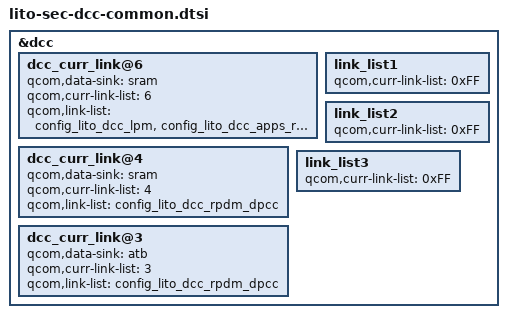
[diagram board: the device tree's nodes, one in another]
/* Copyright (c) 2019, The Linux Foundation. All rights reserved.
 *
 * This program is free software; you can redistribute it and/or modify
 * it under the terms of the GNU General Public License version 2 and
 * only version 2 as published by the Free Software Foundation.
 *
 * This program is distributed in the hope that it will be useful,
 * but WITHOUT ANY WARRANTY; without even the implied warranty of
 * MERCHANTABILITY or FITNESS FOR A PARTICULAR PURPOSE.  See the
 * GNU General Public License for more details.
 */

#include <dt-bindings/soc/qcom,dcc_v2.h>

#define config_lito_dcc_apps_rsc_pdc \
	/* APPS RSC */				\
	<DCC_READ 0x18200010 1 0>,	\
	<DCC_READ 0x18200030 1 0>,	\
	<DCC_READ 0x18200038 1 0>,	\
	<DCC_READ 0x18200040 1 0>,	\
	<DCC_READ 0x18200048 1 0>,	\
	<DCC_READ 0x18200400 1 0>,	\
	<DCC_READ 0x18200404 1 0>,	\
	<DCC_READ 0x18200408 1 0>,	\
	<DCC_READ 0x18220038 1 0>,	\
	<DCC_READ 0x18220040 1 0>,	\
	<DCC_READ 0x182200d0 1 0>,	\
	<DCC_READ 0x18230408 1 0>,	\
								\
	/* RPMH PDC */				\
	<DCC_READ 0xb201020 1 0>,	\
	<DCC_READ 0xb201024 1 0>,	\
	<DCC_READ 0xb20103c 1 0>,	\
	<DCC_READ 0xb204510 1 0>,	\
	<DCC_READ 0xb204514 1 0>,	\
	<DCC_READ 0xb204520 1 0>,	\
	<DCC_READ 0xb231020 1 0>,	\
	<DCC_READ 0xb231024 1 0>

#define config_lito_dcc_lpm		\
	 /* PCU Register */ 		\
	<DCC_READ 0x18000024 1 0>,	\
	<DCC_READ 0x18000040 1 0>,	\
	<DCC_READ 0x18010024 1 0>,	\
	<DCC_READ 0x18010040 1 0>,	\
	<DCC_READ 0x18020024 1 0>,	\
	<DCC_READ 0x18020040 1 0>,	\
	<DCC_READ 0x18030024 1 0>,	\
	<DCC_READ 0x18030040 1 0>,	\
	<DCC_READ 0x18040024 1 0>,	\
	<DCC_READ 0x18040040 1 0>,	\
	<DCC_READ 0x18050024 1 0>,	\
	<DCC_READ 0x18050040 1 0>,	\
	<DCC_READ 0x18060024 1 0>,	\
	<DCC_READ 0x18060040 1 0>,	\
	<DCC_READ 0x18070024 1 0>,	\
	<DCC_READ 0x18070040 1 0>,	\
	<DCC_READ 0x18080024 1 0>,	\
	<DCC_READ 0x18080040 1 0>,	\
	<DCC_READ 0x18080044 1 0>,	\
	<DCC_READ 0x18080048 1 0>,	\
	<DCC_READ 0x1808004c 1 0>,	\
	<DCC_READ 0x18080054 1 0>,	\
	<DCC_READ 0x1808006c 1 0>,	\
	<DCC_READ 0x18080070 1 0>,	\
	<DCC_READ 0x18080074 1 0>,	\
	<DCC_READ 0x18080078 1 0>,	\
	<DCC_READ 0x1808007c 1 0>,	\
	<DCC_READ 0x180800f4 1 0>,	\
	<DCC_READ 0x180800f8 1 0>,	\
	<DCC_READ 0x18080104 1 0>,	\
	<DCC_READ 0x18080118 1 0>,	\
	<DCC_READ 0x1808011c 1 0>,	\
	<DCC_READ 0x18080128 1 0>,	\
	<DCC_READ 0x1808012c 1 0>,	\
	<DCC_READ 0x18080130 1 0>,	\
	<DCC_READ 0x18080134 1 0>,	\
	<DCC_READ 0x18080138 1 0>,	\
	<DCC_READ 0x18080158 1 0>,	\
	<DCC_READ 0x1808015c 1 0>,	\
	<DCC_READ 0x18080168 1 0>,	\
	<DCC_READ 0x18080170 1 0>,	\
	<DCC_READ 0x18080174 1 0>,	\
	<DCC_READ 0x18080188 1 0>,	\
	<DCC_READ 0x1808018c 1 0>,	\
	<DCC_READ 0x18080198 1 0>,	\
	<DCC_READ 0x180801ac 1 0>,	\
	<DCC_READ 0x180801b0 1 0>,	\
	<DCC_READ 0x180801b4 1 0>,	\
	<DCC_READ 0x180801b8 1 0>,	\
	<DCC_READ 0x180801bc 1 0>,	\
	<DCC_READ 0x180801f0 1 0>,	\
	<DCC_READ 0x18280000 1 0>,	\
	<DCC_READ 0x18282000 1 0>,	\
	<DCC_READ 0x18284000 1 0>,	\
	<DCC_READ 0x18286000 1 0>

#define config_lito_dcc_core	\
	/* cpu_seq_sts3 */			\
	<DCC_READ 0x1800004C 1 0>,	\
	<DCC_READ 0x1801004C 1 0>,	\
	<DCC_READ 0x1802004C 1 0>,	\
	<DCC_READ 0x1803004C 1 0>,	\
	<DCC_READ 0x1804004C 1 0>,	\
	<DCC_READ 0x1805004C 1 0>,	\
	<DCC_READ 0x1806004C 1 0>,	\
	<DCC_READ 0x1807004C 1 0>,	\
								\
	/* core hang */				\
	<DCC_READ 0x1800005C 1 0>,	\
	<DCC_READ 0x1801005C 1 0>,	\
	<DCC_READ 0x1802005C 1 0>,	\
	<DCC_READ 0x1803005C 1 0>,	\
	<DCC_READ 0x1804005C 1 0>,	\
	<DCC_READ 0x1805005C 1 0>,	\
	<DCC_READ 0x1806005C 1 0>,	\
	<DCC_READ 0x1807005C 1 0>,	\
	<DCC_READ 0x17C0003C 1 0>,	\
								\
	/* CPRh */					\
	<DCC_READ 0x18101908 1 0>,	\
	<DCC_READ 0x18101C18 1 0>,	\
	<DCC_READ 0x18390810 1 0>,	\
	<DCC_READ 0x18390C50 1 0>,	\
	<DCC_READ 0x18390814 1 0>,	\
	<DCC_READ 0x18390C54 1 0>,	\
	<DCC_READ 0x18390818 1 0>,	\
	<DCC_READ 0x18390C58 1 0>,	\
	<DCC_READ 0x18393A84 2 0>,	\
	<DCC_READ 0x18100908 1 0>,	\
	<DCC_READ 0x18100C18 1 0>,	\
	<DCC_READ 0x183A0810 1 0>,	\
	<DCC_READ 0x183A0C50 1 0>,	\
	<DCC_READ 0x183A0814 1 0>,	\
	<DCC_READ 0x183A0C54 1 0>,	\
	<DCC_READ 0x183A0818 1 0>,	\
	<DCC_READ 0x183A0C58 1 0>,	\
	<DCC_READ 0x183A3A84 2 0>,	\
	<DCC_READ 0x18393500 1 0>,	\
	<DCC_READ 0x18393580 1 0>,	\
	<DCC_READ 0x183A3500 1 0>,	\
	<DCC_READ 0x183A3580 1 0>,	\
								\
	/* Silver / L3 / Gold+ PLL */	\
	<DCC_READ 0x18280000 4 0>,		\
	<DCC_READ 0x18284000 4 0>,		\
	<DCC_READ 0x18286000 4 0>,		\
									\
	/* Gold PLL */					\
	<DCC_READ 0x18282000 4 0>,		\
	<DCC_READ 0x18282028 1 0>,		\
	<DCC_READ 0x18282038 1 0>,		\
	<DCC_READ 0x18282080 5 0>,		\
	<DCC_READ 0x18286000 4 0>,		\
	<DCC_READ 0x18286028 1 0>,		\
	<DCC_READ 0x18286038 1 0>,		\
	<DCC_READ 0x18286080 5 0>,		\
									\
	/* rpmh */						\
	<DCC_READ 0x0C201244 1 0>,		\
	<DCC_READ 0x0C202244 1 0>,		\
	<DCC_READ 0x18300000 1 0>,		\
									\
	/* GOLD */						\
	<DCC_READ 	0x1829208C 1 	0>,	\
	<DCC_WRITE	0x1829209C 0x78 0>,	\
	<DCC_WRITE	0x1829209C 0x0  0>,	\
	<DCC_WRITE	0x18292048 0x1  0>,	\
	<DCC_WRITE	0x18292090 0x0  0>,	\
	<DCC_WRITE	0x18292090 0x25 0>,	\
	<DCC_READ	0x18292098 1 	0>,	\
	<DCC_WRITE	0x18292048 0x1D 0>,	\
	<DCC_WRITE	0x18292090 0x0  0>,	\
	<DCC_WRITE	0x18292090 0x25 0>,	\
	<DCC_READ	0x18292098 1	0>,	\
									\
	/* GOLD+ */						\
	<DCC_READ  0x1829608C 1    0>,	\
	<DCC_WRITE 0x1829609C 0x78 0>,	\
	<DCC_WRITE 0x1829609C 0x0  0>,	\
	<DCC_WRITE 0x18296048 0x1  0>,	\
	<DCC_WRITE 0x18296090 0x0  0>,	\
	<DCC_WRITE 0x18296090 0x25 0>,	\
	<DCC_READ  0x18296098 1	   0>,	\
	<DCC_WRITE 0x18296048 0x1D 0>,	\
	<DCC_WRITE 0x18296090 0x0  0>,	\
	<DCC_WRITE 0x18296090 0x25 0>

#define config_lito_dcc_osm			\
	/* APSS_OSM_RAIN0/RAIL1 */		\
	<DCC_READ 0x1832102c 1 0>,		\
	<DCC_READ 0x18321044 1 0>,		\
	<DCC_READ 0x18321700 1 0>,		\
	<DCC_READ 0x18321710 1 0>,		\
	<DCC_READ 0x1832176c 1 0>,		\
	<DCC_READ 0x18321818 1 0>,		\
	<DCC_READ 0x18321920 1 0>,		\
	<DCC_READ 0x18322c18 1 0>,		\
	<DCC_READ 0x1832302c 1 0>,		\
	<DCC_READ 0x18323044 1 0>,		\
	<DCC_READ 0x18323700 1 0>,		\
	<DCC_READ 0x18323710 1 0>,		\
	<DCC_READ 0x1832376c 1 0>,		\
	<DCC_READ 0x18323818 1 0>,		\
	<DCC_READ 0x18323920 1 0>,		\
	<DCC_READ 0x18324c18 1 0>,		\
	<DCC_READ 0x1832582c 1 0>,		\
	<DCC_READ 0x18325844 1 0>,		\
	<DCC_READ 0x18325f00 1 0>,		\
	<DCC_READ 0x18325f10 1 0>,		\
	<DCC_READ 0x18325f6c 1 0>,		\
	<DCC_READ 0x18326018 1 0>,		\
	<DCC_READ 0x18326120 1 0>,		\
	<DCC_READ 0x18327418 1 0>,		\
	<DCC_READ 0x1832782c 1 0>,		\
	<DCC_READ 0x18327844 1 0>,		\
	<DCC_READ 0x18327f00 1 0>,		\
	<DCC_READ 0x18327f10 1 0>,		\
	<DCC_READ 0x18327f6c 1 0>,		\
	<DCC_READ 0x18328018 1 0>,		\
	<DCC_READ 0x18328120 1 0>,		\
	<DCC_READ 0x18329418 1 0>

#define	config_lito_dcc_gemnoc		\
	/* GemNOC for lito start */		\
	<DCC_READ	0x9680000	3 0>,	\
	<DCC_LOOP	8 0 0>,				\
	<DCC_READ	0x9681000	1 0>,	\
	<DCC_LOOP	18 0 0>,			\
	<DCC_READ	0x09680078 	1 0>,	\
	<DCC_READ	0x9681008	12 0>,	\
	<DCC_LOOP	0xA6 0 0>,			\
	<DCC_READ	0x9681008 	1 0>,	\
	<DCC_READ	0x968100C 	1 0>,	\
	<DCC_LOOP	1 0 0>,				\
	<DCC_READ	0x968103C 	1 0>,	\
	<DCC_READ	0x9698100 	1 0>,	\
	<DCC_READ	0x9698104 	1 0>,	\
	<DCC_READ	0x9698108 	1 0>,	\
	<DCC_READ	0x9698110 	1 0>,	\
	<DCC_READ	0x9698120 	1 0>,	\
	<DCC_READ	0x9698124 	1 0>,	\
	<DCC_READ	0x9698128 	1 0>,	\
	<DCC_READ	0x969812c 	1 0>,	\
	<DCC_READ	0x9698130 	1 0>,	\
	<DCC_READ	0x9698134 	1 0>,	\
	<DCC_READ	0x9698138 	1 0>,	\
	<DCC_READ	0x969813c 	1 0>,	\
	<DCC_READ	0x968008C 	1 0>,	\
	<DCC_READ	0x9680088 	1 0>,	\
	<DCC_READ	0x96BA090 	1 0>

#define config_lito_dcc_noc			\
	<DCC_READ	0x0010500C	1 0>,	\
	<DCC_READ	0x00104144	1 0>,	\
	<DCC_READ	0x00105034	1 0>,	\
	/* Enable GCC_AGGRE_NOC_AHB_CBCR */	\
	<DCC_READ	0x00182008 	1 0>,	\
									\
	/* Enable clocks for SNOC sense registers */	\
	<DCC_WRITE	0x0010500C 0x1  0>,	\
	<DCC_WRITE	0x00104144 0x1  0>,	\
	<DCC_WRITE	0x00105034 0x1  0>,	\
	/* Enable GCC_AGGRE_NOC_AHB_CBCR */	\
	<DCC_WRITE	0x00182008 0x1  0>,	\
									\
	/* A1NOC */						\
	<DCC_READ	0x16e0000	1 0>,	\
	<DCC_READ	0x16e0004	1 0>,	\
	<DCC_READ	0x16e0288	1 0>,	\
	<DCC_READ	0x16e0290	1 0>,	\
	<DCC_READ	0x16e0300	1 0>,	\
	<DCC_READ	0x16e0408	1 0>,	\
	<DCC_READ	0x16e0410	1 0>,	\
	<DCC_READ	0x16e0420	1 0>,	\
	<DCC_READ	0x16e0424	1 0>,	\
	<DCC_READ	0x16e0428	1 0>,	\
	<DCC_READ	0x16e042c	1 0>,	\
	<DCC_READ	0x16e0430	1 0>,	\
	<DCC_READ	0x16e0434	1 0>,	\
	<DCC_READ	0x16e0438	1 0>,	\
	<DCC_READ	0x16e043c	1 0>,	\
	<DCC_READ	0x16e0688	1 0>,	\
	<DCC_READ	0x16e0690	1 0>,	\
	<DCC_READ	0x16e0700	1 0>,	\
	<DCC_READ	0x16e0888	1 0>,	\
	<DCC_READ	0x16e0890	1 0>,	\
	<DCC_READ	0x16e0900	1 0>,	\
	<DCC_READ	0x16e0904	1 0>,	\
	<DCC_READ	0x16e0a40	1 0>,	\
	<DCC_READ	0x16e0a48	1 0>,	\
	<DCC_READ	0x16e0a88	1 0>,	\
	<DCC_READ	0x16e0a90	1 0>,	\
	<DCC_READ	0x16e0b00	1 0>,	\
									\
	/* A2NOC */						\
	<DCC_READ 0x1700204	1 0>,		\
	<DCC_READ 0x1700240	1 0>,		\
	<DCC_READ 0x1700248	1 0>,		\
	<DCC_READ 0x1700288	1 0>,		\
	<DCC_READ 0x1700290	1 0>,		\
	<DCC_READ 0x1700300	1 0>,		\
	<DCC_READ 0x1700304	1 0>,		\
	<DCC_READ 0x1700308	1 0>,		\
	<DCC_READ 0x170030c	1 0>,		\
	<DCC_READ 0x1700310	1 0>,		\
	<DCC_READ 0x1700400	1 0>,		\
	<DCC_READ 0x1700404	1 0>,		\
	<DCC_READ 0x1700488	1 0>,		\
	<DCC_READ 0x1700490	1 0>,		\
	<DCC_READ 0x1700500	1 0>,		\
	<DCC_READ 0x1700504	1 0>,		\
	<DCC_READ 0x1700508	1 0>,		\
	<DCC_READ 0x170050c	1 0>,		\
	<DCC_READ 0x1700c00	1 0>,		\
	<DCC_READ 0x1700c04	1 0>,		\
	<DCC_READ 0x1700c08	1 0>,		\
	<DCC_READ 0x1700c10	1 0>,		\
	<DCC_READ 0x1700c20	1 0>,		\
	<DCC_READ 0x1700c24	1 0>,		\
	<DCC_READ 0x1700c28	1 0>,		\
	<DCC_READ 0x1700c2c	1 0>,		\
	<DCC_READ 0x1700c30	1 0>,		\
	<DCC_READ 0x1700c34	1 0>,		\
	<DCC_READ 0x1700c38	1 0>,		\
	<DCC_READ 0x1700c3c	1 0>,		\
									\
	/* SNOC */						\
	<DCC_READ	0x1620000	1 0>,	\
	<DCC_READ	0x1620004	1 0>,	\
	<DCC_READ	0x1620008	1 0>,	\
	<DCC_READ	0x1620010	1 0>,	\
	<DCC_READ	0x1620020	1 0>,	\
	<DCC_READ	0x1620024	1 0>,	\
	<DCC_READ	0x1620028	1 0>,	\
	<DCC_READ	0x162002c	1 0>,	\
	<DCC_READ	0x1620030	1 0>,	\
	<DCC_READ	0x1620034	1 0>,	\
	<DCC_READ	0x1620038	1 0>,	\
	<DCC_READ	0x162003c	1 0>,	\
	<DCC_READ	0x1620100	1 0>,	\
	<DCC_READ	0x1620104	1 0>,	\
	<DCC_READ	0x1620108	1 0>,	\
	<DCC_READ	0x1620110	1 0>,	\
	<DCC_READ	0x1620200	1 0>,	\
	<DCC_READ	0x1620204	1 0>,	\
	<DCC_READ	0x1620240	1 0>,	\
	<DCC_READ	0x1620248	1 0>,	\
	<DCC_READ	0x1620288	1 0>,	\
	<DCC_READ	0x162028c	1 0>,	\
	<DCC_READ	0x1620290	1 0>,	\
	<DCC_READ	0x1620294	1 0>,	\
	<DCC_READ	0x16202a8	1 0>,	\
	<DCC_READ	0x16202ac	1 0>,	\
	<DCC_READ	0x16202b0	1 0>,	\
	<DCC_READ	0x16202b4	1 0>,	\
	<DCC_READ	0x1620300	1 0>,	\
	<DCC_READ	0x1620400	1 0>,	\
	<DCC_READ	0x1620404	1 0>,	\
	<DCC_READ	0x1620488	1 0>,	\
	<DCC_READ	0x1620490	1 0>,	\
	<DCC_READ	0x1620500	1 0>,	\
	<DCC_READ	0x1620504	1 0>,	\
	<DCC_READ	0x1620508	1 0>,	\
	<DCC_READ	0x162050c	1 0>,	\
	<DCC_READ	0x1620510	1 0>,	\
	<DCC_READ	0x1620600	1 0>,	\
	<DCC_READ	0x1620604	1 0>,	\
	<DCC_READ	0x1620688	1 0>,	\
	<DCC_READ	0x1620690	1 0>,	\
	<DCC_READ	0x1620700	1 0>,	\
	<DCC_READ	0x1620704	1 0>,	\
	<DCC_READ	0x1620708	1 0>,	\
	<DCC_READ	0x162070c	1 0>,	\
	<DCC_READ	0x1620710	1 0>,	\
	<DCC_READ	0x1620800	1 0>,	\
	<DCC_READ	0x1620804	1 0>,	\
	<DCC_READ	0x1620900	1 0>,	\
	<DCC_READ	0x1620a00	1 0>,	\
	<DCC_READ	0x1620a04	1 0>,	\
	<DCC_READ	0x1620b00	1 0>,	\
	<DCC_READ	0x1620b04	1 0>,	\
	<DCC_READ	0x1620e00	1 0>,	\
	<DCC_READ	0x1620e04	1 0>,	\
	<DCC_READ	0x1620e88	1 0>,	\
	<DCC_READ	0x1620e90	1 0>,	\
	<DCC_READ	0x1620f00	1 0>,	\
	<DCC_READ	0x1639000	1 0>,	\
	<DCC_READ	0x1639004	1 0>,	\
	<DCC_READ	0x1639088	1 0>,	\
	<DCC_READ	0x1639090	1 0>,	\
	<DCC_READ	0x1639100	1 0>,	\
									\
	/* LPASS AGNOC */				\
	<DCC_READ	0x3c41800	1 0>,	\
	<DCC_READ	0x3c41804	1 0>,	\
	<DCC_READ	0x3c41880	1 0>,	\
	<DCC_READ	0x3c41888	1 0>,	\
	<DCC_READ	0x3c41890	1 0>,	\
	<DCC_READ	0x3c41900	1 0>,	\
	<DCC_READ	0x3c41a00	1 0>,	\
	<DCC_READ	0x3c41a04	1 0>,	\
	<DCC_READ	0x3c41a40	1 0>,	\
	<DCC_READ	0x3c41a48	1 0>,	\
	<DCC_READ	0x3c41c00	1 0>,	\
	<DCC_READ	0x3c41c04	1 0>,	\
	<DCC_READ	0x3c41d00	1 0>,	\
	<DCC_READ	0x3c42680	1 0>,	\
	<DCC_READ	0x3c42684	1 0>,	\
	<DCC_READ	0x3c42688	1 0>,	\
	<DCC_READ	0x3c42690	1 0>,	\
	<DCC_READ	0x3c42698	1 0>,	\
	<DCC_READ	0x3c426a0	1 0>,	\
	<DCC_READ	0x3c426a4	1 0>,	\
	<DCC_READ	0x3c426a8	1 0>,	\
	<DCC_READ	0x3c426ac	1 0>,	\
	<DCC_READ	0x3c426b0	1 0>,	\
	<DCC_READ	0x3c426b4	1 0>,	\
	<DCC_READ	0x3c426b8	1 0>,	\
	<DCC_READ	0x3c426bc	1 0>,	\
									\
	/* MMSS NOC */					\
	<DCC_READ 0x1740000 1 0>,  \
	<DCC_READ 0x1740004 1 0>,  \
	<DCC_READ 0x1740008 1 0>,  \
	<DCC_READ 0x1740010 1 0>,  \
	<DCC_READ 0x1740018 1 0>,  \
	<DCC_READ 0x1740020 1 0>,  \
	<DCC_READ 0x1740024 1 0>,  \
	<DCC_READ 0x1740028 1 0>,  \
	<DCC_READ 0x174002c 1 0>,  \
	<DCC_READ 0x1740030 1 0>,  \
	<DCC_READ 0x1740034 1 0>,  \
	<DCC_READ 0x1740038 1 0>,  \
	<DCC_READ 0x174003c 1 0>,  \
	<DCC_READ 0x1740240 1 0>,  \
	<DCC_READ 0x1740248 1 0>,  \
	<DCC_READ 0x1740280 1 0>,  \
	<DCC_READ 0x1740288 1 0>,  \
	<DCC_READ 0x1740290 1 0>,  \
	<DCC_READ 0x1740300 1 0>,  \
	<DCC_READ 0x1740304 1 0>,  \
	<DCC_READ 0x1740308 1 0>,  \
	<DCC_READ 0x174030c 1 0>,  \
	<DCC_READ 0x1740310 1 0>,  \
	<DCC_READ 0x1740314 1 0>,  \
	<DCC_READ 0x1740318 1 0>,  \
					\
	/* DDR NOC */								\
	<DCC_READ 0x010B8020 1 0>,  \
	<DCC_READ 0x010B8024 1 0>,  \
	<DCC_READ 0x010B8028 1 0>,  \
	<DCC_READ 0x010B802C 1 0>,  \
	<DCC_READ 0x010B8030 1 0>,  \
	<DCC_READ 0x010B8034 1 0>,  \
	<DCC_READ 0x010B8038 1 0>,  \
	<DCC_READ 0x010B803C 1 0>,  \
	<DCC_READ 0x010B8050 1 0>,  \
					\
	/* SMMU NOC */							\
	<DCC_READ 0x010B80A0 1 0>,  \
	<DCC_READ 0x010B80A4 1 0>,  \
	<DCC_READ 0x010B80A8 1 0>,  \
	<DCC_READ 0x010B80AC 1 0>,  \
	<DCC_READ 0x010B80B0 1 0>,  \
	<DCC_READ 0x010B80B4 1 0>,  \
	<DCC_READ 0x010B80B8 1 0>,  \
	<DCC_READ 0x010B80BC 1 0>,  \
	<DCC_READ 0x010B80E0 1 0>,  \
					\
	/* GEMNOC */					\
	<DCC_READ 0x9681010 1 0>,		\
	<DCC_READ 0x9681014 1 0>,		\
	<DCC_READ 0x9681018 1 0>,		\
	<DCC_READ 0x968101c 1 0>,		\
	<DCC_READ 0x9681020 1 0>,		\
	<DCC_READ 0x9681024 1 0>,		\
	<DCC_READ 0x9681028 1 0>,		\
	<DCC_READ 0x968102c 1 0>,		\
	<DCC_READ 0x9681030 1 0>,		\
	<DCC_READ 0x9681034 1 0>,		\
	<DCC_READ 0x968103c 1 0>,		\
	<DCC_READ 0x9692000 1 0>,		\
	<DCC_READ 0x9692004 1 0>,		\
	<DCC_READ 0x9692008 1 0>,		\
	<DCC_READ 0x9692040 1 0>,		\
	<DCC_READ 0x9692048 1 0>,		\
	<DCC_READ 0x9695000 1 0>,		\
	<DCC_READ 0x9695004 1 0>,		\
	<DCC_READ 0x9695080 1 0>,		\
	<DCC_READ 0x9695084 1 0>,		\
	<DCC_READ 0x9695088 1 0>,		\
	<DCC_READ 0x969508c 1 0>,		\
	<DCC_READ 0x9695090 1 0>,		\
	<DCC_READ 0x9695094 1 0>,		\
	<DCC_READ 0x96950a0 1 0>,		\
	<DCC_READ 0x96950a8 1 0>,		\
	<DCC_READ 0x96950b0 1 0>,		\
	<DCC_READ 0x9695100 1 0>,		\
	<DCC_READ 0x9695104 1 0>,		\
	<DCC_READ 0x9695108 1 0>,		\
	<DCC_READ 0x969510c 1 0>,		\
	<DCC_READ 0x9695110 1 0>,		\
	<DCC_READ 0x9695114 1 0>,		\
	<DCC_READ 0x9695118 1 0>,		\
	<DCC_READ 0x969511c 1 0>,		\
	<DCC_READ 0x9696000 1 0>,		\
	<DCC_READ 0x9696004 1 0>,		\
	<DCC_READ 0x9696080 1 0>,		\
	<DCC_READ 0x9696088 1 0>,		\
	<DCC_READ 0x9696090 1 0>,		\
	<DCC_READ 0x9696100 1 0>,		\
	<DCC_READ 0x9696104 1 0>,		\
	<DCC_READ 0x9696108 1 0>,		\
	<DCC_READ 0x969610c 1 0>,		\
	<DCC_READ 0x9696114 1 0>,		\
	<DCC_READ 0x9696118 1 0>,		\
	<DCC_READ 0x969611c 1 0>,		\
	<DCC_READ 0x9698000 1 0>,		\
	<DCC_READ 0x9698004 1 0>,		\
	<DCC_READ 0x9698008 1 0>,		\
	<DCC_READ 0x9698010 1 0>,		\
	<DCC_READ 0x9698100 1 0>,		\
	<DCC_READ 0x9698104 1 0>,		\
	<DCC_READ 0x9698108 1 0>,		\
	<DCC_READ 0x9698110 1 0>,		\
	<DCC_READ 0x9698118 1 0>,		\
	<DCC_READ 0x9698120 1 0>,		\
	<DCC_READ 0x9698124 1 0>,		\
	<DCC_READ 0x9698128 1 0>,		\
	<DCC_READ 0x969812c 1 0>,		\
	<DCC_READ 0x9698130 1 0>,		\
	<DCC_READ 0x9698134 1 0>,		\
	<DCC_READ 0x9698138 1 0>,		\
	<DCC_READ 0x969813c 1 0>,		\
	<DCC_READ 0x9698200 1 0>,		\
	<DCC_READ 0x9698204 1 0>,		\
	<DCC_READ 0x9698240 1 0>,		\
	<DCC_READ 0x9698244 1 0>,		\
	<DCC_READ 0x9698248 1 0>,		\
	<DCC_READ 0x969824c 1 0>,		\
	<DCC_READ 0x9232100 1 0>,		\
	<DCC_READ 0x9236044 1 0>,		\
	<DCC_READ 0x9236048 1 0>,		\
	<DCC_READ 0x923604C 1 0>,		\
	<DCC_READ 0x9236054 1 0>,		\
	<DCC_READ 0x9236040 1 0>,		\
	<DCC_READ 0x923A01C 1 0>,		\
	<DCC_READ 0x923A014 1 0>,		\
	<DCC_READ 0x923A004 1 0>,		\
	<DCC_READ 0x923A008 1 0>,		\
	<DCC_READ 0x923A00C 1 0>,		\
	<DCC_READ 0x923A010 1 0>,		\
	<DCC_READ 0x924202C 1 0>,		\
	<DCC_READ 0x922320C 1 0>,		\
	<DCC_READ 0x962320C 1 0>,		\
	<DCC_READ 0x9242014 1 0>,		\
	<DCC_READ 0x9242018 1 0>,		\
	<DCC_READ 0x924201C 1 0>,		\
	<DCC_READ 0x9242028 1 0>,		\
	<DCC_READ 0x924202C 1 0>,		\
	<DCC_READ 0x9242090 1 0>,		\
	<DCC_READ 0x9242094 1 0>,		\
	<DCC_READ 0x9242098 1 0>,		\
	<DCC_READ 0x92420A0 1 0>,		\
	<DCC_READ 0x92420B4 1 0>,		\
	<DCC_READ 0x92420C0 1 0>,		\
	<DCC_READ 0x92420D0 1 0>,		\
	<DCC_READ 0x92420D4 1 0>,		\
	<DCC_READ 0x92420D8 1 0>,		\
	<DCC_READ 0x9244054 1 0>,		\
	<DCC_READ 0x9236028 1 0>,		\
	<DCC_READ 0x923602C 1 0>,		\
	<DCC_READ 0x9236030 1 0>,		\
	<DCC_READ 0x9236034 1 0>,		\
	<DCC_READ 0x9236038 1 0>,		\
	<DCC_READ 0x923603C 1 0>,		\
	<DCC_READ 0x9236050 1 0>,		\
	<DCC_READ 0x9236058 1 0>,		\
	<DCC_READ 0x923605C 1 0>,		\
	<DCC_READ 0x9236060 1 0>,		\
	<DCC_READ 0x9236064 1 0>,		\
	<DCC_READ 0x9236068 1 0>,		\
	<DCC_READ 0x923606C 1 0>,		\
	<DCC_READ 0x9236070 1 0>,		\
	<DCC_READ 0x9236088 1 0>,		\
	<DCC_READ 0x92360A0 1 0>,		\
	<DCC_READ 0x92370A4 1 0>,		\
	<DCC_READ 0x923201C 1 0>,		\
	<DCC_READ 0x9232020 1 0>,		\
	<DCC_READ 0x9232024 1 0>,		\
	<DCC_READ 0x9232028 1 0>,		\
	<DCC_READ 0x923202C 1 0>,		\
	<DCC_READ 0x9232050 1 0>,		\
	<DCC_READ 0x9232104 1 0>,		\
	<DCC_READ 0x9232108 1 0>,		\
	<DCC_READ 0x923210C 1 0>,		\
	<DCC_READ 0x9232110 1 0>,		\
	<DCC_READ 0x9232114 1 0>,		\
	<DCC_READ 0x9200004 1 0>,		\
	<DCC_READ 0x9220338 1 0>,		\
	<DCC_READ 0x922033C 1 0>,		\
	<DCC_READ 0x9220344 1 0>,		\
	<DCC_READ 0x9220348 1 0>,		\
	<DCC_READ 0x9220480 1 0>,		\
	<DCC_READ 0x9222330 1 0>,		\
	<DCC_READ 0x9222334 1 0>,		\
	<DCC_READ 0x9222398 1 0>,		\
	<DCC_READ 0x92223A4 1 0>,		\
	<DCC_READ 0x9222400 1 0>,		\
	<DCC_READ 0x9222404 1 0>,		\
	<DCC_READ 0x9222408 1 0>,		\
	<DCC_READ 0x922240C 1 0>,		\
	<DCC_READ 0x9222410 1 0>,		\
	<DCC_READ 0x9222414 1 0>,		\
	<DCC_READ 0x9222600 1 0>,		\
	<DCC_READ 0x922320C 1 0>,		\
	<DCC_READ 0x9223214 1 0>,		\
	<DCC_READ 0x9223218 1 0>,		\
	<DCC_READ 0x9223220 1 0>,		\
	<DCC_READ 0x9223224 1 0>,		\
	<DCC_READ 0x9223228 1 0>,		\
	<DCC_READ 0x9223308 1 0>,		\
	<DCC_READ 0x9223318 1 0>,		\
	<DCC_READ 0x922358C 1 0>,		\
	<DCC_READ 0x92C2014 1 0>,		\
	<DCC_READ 0x92C2018 1 0>,		\
	<DCC_READ 0x92C201C 1 0>,		\
	<DCC_READ 0x92C2028 1 0>,		\
	<DCC_READ 0x92C202C 1 0>,		\
	<DCC_READ 0x92C2090 1 0>,		\
	<DCC_READ 0x92C2094 1 0>,		\
	<DCC_READ 0x92C2098 1 0>,		\
	<DCC_READ 0x92C20A0 1 0>,		\
	<DCC_READ 0x92C20B4 1 0>,		\
	<DCC_READ 0x92C20C0 1 0>,		\
	<DCC_READ 0x92C20D0 1 0>,		\
	<DCC_READ 0x92C20D4 1 0>,		\
	<DCC_READ 0x92C20D8 1 0>,		\
	<DCC_READ 0x92C4054 1 0>,		\
	<DCC_READ 0x92B6028 1 0>,		\
	<DCC_READ 0x92B602C 1 0>,		\
	<DCC_READ 0x92B6030 1 0>,		\
	<DCC_READ 0x92B6034 1 0>,		\
	<DCC_READ 0x92B6038 1 0>,		\
	<DCC_READ 0x92B603C 1 0>,		\
	<DCC_READ 0x92B6040 1 0>,		\
	<DCC_READ 0x92B6044 1 0>,		\
	<DCC_READ 0x92B6048 1 0>,		\
	<DCC_READ 0x92B604C 1 0>,		\
	<DCC_READ 0x92B6050 1 0>,		\
	<DCC_READ 0x92B6054 1 0>,		\
	<DCC_READ 0x92B6058 1 0>,		\
	<DCC_READ 0x92B605C 1 0>,		\
	<DCC_READ 0x92B6060 1 0>,		\
	<DCC_READ 0x92B6064 1 0>,		\
	<DCC_READ 0x92B6068 1 0>,		\
	<DCC_READ 0x92B606C 1 0>,		\
	<DCC_READ 0x92B6070 1 0>,		\
	<DCC_READ 0x92B6088 1 0>,		\
	<DCC_READ 0x92B60A0 1 0>,		\
	<DCC_READ 0x92B70A4 1 0>,		\
	<DCC_READ 0x92B201C 1 0>,		\
	<DCC_READ 0x92B2020 1 0>,		\
	<DCC_READ 0x92B2024 1 0>,		\
	<DCC_READ 0x92B2028 1 0>,		\
	<DCC_READ 0x92B202C 1 0>,		\
	<DCC_READ 0x92B2050 1 0>,		\
	<DCC_READ 0x92B2100 1 0>,		\
	<DCC_READ 0x92B2104 1 0>,		\
	<DCC_READ 0x92B2108 1 0>,		\
	<DCC_READ 0x92B210C 1 0>,		\
	<DCC_READ 0x92B2110 1 0>,		\
	<DCC_READ 0x92B2114 1 0>,		\
	<DCC_READ 0x9280004 1 0>,		\
	<DCC_READ 0x92A0338 1 0>,		\
	<DCC_READ 0x92A033C 1 0>,		\
	<DCC_READ 0x92A0344 1 0>,		\
	<DCC_READ 0x92A0348 1 0>,		\
	<DCC_READ 0x92A0480 1 0>,		\
	<DCC_READ 0x92A2330 1 0>,		\
	<DCC_READ 0x92A2334 1 0>,		\
	<DCC_READ 0x92A2398 1 0>,		\
	<DCC_READ 0x92A23A4 1 0>,		\
	<DCC_READ 0x92A2400 1 0>,		\
	<DCC_READ 0x92A2404 1 0>,		\
	<DCC_READ 0x92A2408 1 0>,		\
	<DCC_READ 0x92A240C 1 0>,		\
	<DCC_READ 0x92A2410 1 0>,		\
	<DCC_READ 0x92A2414 1 0>,		\
	<DCC_READ 0x92A2600 1 0>,		\
	<DCC_READ 0x92A320C 1 0>,		\
	<DCC_READ 0x92A3214 1 0>,		\
	<DCC_READ 0x92A3218 1 0>,		\
	<DCC_READ 0x92A3220 1 0>,		\
	<DCC_READ 0x92A3224 1 0>,		\
	<DCC_READ 0x92A3228 1 0>,		\
	<DCC_READ 0x92A3308 1 0>,		\
	<DCC_READ 0x92A3318 1 0>,		\
	<DCC_READ 0x92A358C 1 0>,		\
	<DCC_READ 0x92BA01C 1 0>,		\
	<DCC_READ 0x92BA014 1 0>,		\
	<DCC_READ 0x92BA004 1 0>,		\
	<DCC_READ 0x92BA008 1 0>,		\
	<DCC_READ 0x92BA00C 1 0>,		\
	<DCC_READ 0x92BA010 1 0>,		\
	<DCC_READ 0x963A01C 1 0>,		\
	<DCC_READ 0x964202C 1 0>,		\
	<DCC_READ 0x968008C 1 0>,		\
	<DCC_READ 0x9680088 1 0>,		\
	<DCC_READ 0x96950B0 1 0>,		\
	<DCC_READ 0x96AD010 1 0>,		\
	<DCC_READ 0x96AE010 1 0>,		\
	<DCC_READ 0x96AE090 1 0>,		\
	<DCC_READ 0x96AF010 1 0>,		\
	<DCC_READ 0x96B0010 1 0>,		\
	<DCC_READ 0x96B1010 1 0>,		\
	<DCC_READ 0x96B1090 1 0>,		\
	<DCC_READ 0x96B2010 1 0>,		\
	<DCC_READ 0x96B3010 1 0>,		\
	<DCC_READ 0x96B4010 1 0>,		\
	<DCC_READ 0x96B5010 1 0>,		\
	<DCC_READ 0x96B5090 1 0>,		\
	<DCC_READ 0x96B6010 1 0>,		\
	<DCC_READ 0x96B7010 1 0>,		\
	<DCC_READ 0x96B8010 1 0>,		\
	<DCC_READ 0x96AC008 1 0>,		\
	<DCC_READ 0x96AC040 1 0>,		\
	<DCC_READ 0x96AC044 1 0>,		\
	<DCC_READ 0x96AC048 1 0>,		\
	<DCC_READ 0x96AC04C 1 0>,		\
	<DCC_READ 0x96AC050 1 0>,		\
	<DCC_READ 0x96AC054 1 0>,		\
	<DCC_READ 0x96AC058 1 0>,		\
	<DCC_READ 0x96AC05C 1 0>,		\
	<DCC_READ 0x96AC060 1 0>,		\
	<DCC_READ 0x96AC064 1 0>,		\
	<DCC_READ 0x96AC068 1 0>,		\
	<DCC_READ 0x96AC06C 1 0>,		\
	<DCC_READ 0x96AC208 1 0>,		\
	<DCC_READ 0x96AC240 1 0>,		\
	<DCC_READ 0x96AC244 1 0>,		\
	<DCC_READ 0x96AC248 1 0>,		\
	<DCC_READ 0x96AC24C 1 0>,		\
	<DCC_READ 0x96AC250 1 0>,		\
	<DCC_READ 0x96AC254 1 0>,		\
	<DCC_READ 0x96AC258 1 0>,		\
	<DCC_READ 0x96AC25C 1 0>,		\
	<DCC_READ 0x96AC260 1 0>,		\
	<DCC_READ 0x96AC264 1 0>,		\
	<DCC_READ 0x96AC268 1 0>,		\
	<DCC_READ 0x96AC26C 1 0>,		\
	<DCC_READ 0x96950A8 1 0>,		\
	<DCC_READ 0x96950B0 1 0>,		\
	<DCC_READ 0x96950A0 1 0>,		\
	<DCC_READ 0x9180740 1 0>,		\
	<DCC_READ 0x9181740 1 0>,		\
	<DCC_READ 0x9182740 1 0>,		\
	<DCC_READ 0x9183740 1 0>,		\
	<DCC_READ 0x9184740 1 0>,		\
	<DCC_READ 0x9185740 1 0>,		\
	<DCC_READ 0x0148064 1 0>,		\
	<DCC_READ 0x014401C 1 0>,		\
	<DCC_READ 0x9681004 1 0>,		\
	<DCC_READ 0x9235030 1 0>,		\
	<DCC_READ 0x9235034 1 0>,		\
	<DCC_READ 0x92B5030 1 0>,		\
	<DCC_READ 0x92B5034 1 0>,		\
	<DCC_READ 0x9648074 1 0>,		\
	<DCC_READ 0x9248074 1 0>,		\
	<DCC_READ 0x92C8074 1 0>,		\
	<DCC_READ 0x9248068 1 0>,		\
	<DCC_READ 0x92C8068 1 0>,		\
	<DCC_READ 0x9648068 1 0>,		\
	<DCC_READ 0x92BA018 1 0>,		\
	<DCC_READ 0x963A018 1 0>,		\
	<DCC_READ 0x923A018 1 0>,		\
	<DCC_READ 0x9230010 1 0>,		\
	<DCC_READ 0x9230020 1 0>,		\
	<DCC_READ 0x9230030 1 0>,		\
	<DCC_READ 0x9230040 1 0>,		\
	<DCC_READ 0x923001C 1 0>,		\
	<DCC_READ 0x923002C 1 0>,		\
	<DCC_READ 0x923003C 1 0>,		\
	<DCC_READ 0x923004C 1 0>,		\
	<DCC_READ 0x17A70200 1 0>,		\
	<DCC_READ 0x17A90200 1 0>,		\
	<DCC_READ 0x17AB0200 1 0>,		\
	<DCC_READ 0x17AD0200 1 0>,		\
	<DCC_READ 0x17AF0200 1 0>,		\
	<DCC_READ 0x17B10200 1 0>,		\
	<DCC_READ 0x17B30200 1 0>,		\
	<DCC_READ 0x17B50200 1 0>

#define config_lito_dcc_gcc			\
	/* GCC */						\
	<DCC_READ 0x100000 13 0>,		\
	<DCC_READ 0x100040 	1	0>,		\
	<DCC_READ 0x100100  4 0>,		\
	<DCC_READ 0x101000 13 0>,		\
	<DCC_READ 0x10103c  1 0>,		\
	<DCC_READ 0x101040  1 0>,		\
	<DCC_READ 0x102000 13 0>,		\
	<DCC_READ 0x10203c  1 0>,		\
	<DCC_READ 0x102040  1 0>,		\
	<DCC_READ 0x103000 13 0>,		\
	<DCC_READ 0x10303c  1 0>,		\
	<DCC_READ 0x103040  1 0>,		\
	<DCC_READ 0x10401c  1 0>,		\
	<DCC_READ 0x105008  1 0>,		\
	<DCC_READ 0x10504c  1 0>,		\
	<DCC_READ 0x105064  1 0>,		\
	<DCC_READ 0x106100  1 0>,		\
	<DCC_READ 0x109004  1 0>,		\
	<DCC_READ 0x109008  1 0>,		\
	<DCC_READ 0x10900c  1 0>,		\
	<DCC_READ 0x109010  1 0>,		\
	<DCC_READ 0x109014  1 0>,		\
	<DCC_READ 0x109018  1 0>,		\
	<DCC_READ 0x10901c  1 0>,		\
	<DCC_READ 0x109020  1 0>,		\
	<DCC_READ 0x109024  1 0>,		\
	<DCC_READ 0x10904c  1 0>,		\
	<DCC_READ 0x10915c  1 0>,		\
	<DCC_READ 0x109160  1 0>,		\
	<DCC_READ 0x109464  1 0>,		\
	<DCC_READ 0x109468  1 0>,		\
	<DCC_READ 0x10946c  1 0>,		\
	<DCC_READ 0x109470  1 0>,		\
	<DCC_READ 0x109478  1 0>,		\
	<DCC_READ 0x113000  1 0>,		\
	<DCC_READ 0x113004  1 0>,		\
	<DCC_READ 0x113008  1 0>,		\
	<DCC_READ 0x11300c  1 0>,		\
	<DCC_READ 0x113010  1 0>,		\
	<DCC_READ 0x113014  1 0>,		\
	<DCC_READ 0x113018  1 0>,		\
	<DCC_READ 0x11301c  1 0>,		\
	<DCC_READ 0x113020  1 0>,		\
	<DCC_READ 0x113024  1 0>,		\
	<DCC_READ 0x113028  1 0>,		\
	<DCC_READ 0x11302c  1 0>,		\
	<DCC_READ 0x113030  1 0>,		\
	<DCC_READ 0x11303c  1 0>,		\
	<DCC_READ 0x113040  1 0>,		\
	<DCC_READ 0x117024  1 0>,		\
	<DCC_READ 0x117154  1 0>,		\
	<DCC_READ 0x117284  1 0>,		\
	<DCC_READ 0x1173b4  1 0>,		\
	<DCC_READ 0x1174e4  1 0>,		\
	<DCC_READ 0x117614  1 0>,		\
	<DCC_READ 0x118024  1 0>,		\
	<DCC_READ 0x118154  1 0>,		\
	<DCC_READ 0x118284  1 0>,		\
	<DCC_READ 0x1183b4  1 0>,		\
	<DCC_READ 0x1184e4  1 0>,		\
	<DCC_READ 0x118614  1 0>,		\
	<DCC_READ 0x11a000  1 0>,		\
	<DCC_READ 0x11a004  1 0>,		\
	<DCC_READ 0x11a008  1 0>,		\
	<DCC_READ 0x11a00c  1 0>,		\
	<DCC_READ 0x11a010  1 0>,		\
	<DCC_READ 0x11a014  1 0>,		\
	<DCC_READ 0x11a018  1 0>,		\
	<DCC_READ 0x11a01c  1 0>,		\
	<DCC_READ 0x11a020  1 0>,		\
	<DCC_READ 0x11a024  1 0>,		\
	<DCC_READ 0x11a028  1 0>,		\
	<DCC_READ 0x11a02c  1 0>,		\
	<DCC_READ 0x11a030  1 0>,		\
	<DCC_READ 0x11a03c  1 0>,		\
	<DCC_READ 0x11a040  1 0>,		\
	<DCC_READ 0x11b000  1 0>,		\
	<DCC_READ 0x11b004  1 0>,		\
	<DCC_READ 0x11b008  1 0>,		\
	<DCC_READ 0x11b00c  1 0>,		\
	<DCC_READ 0x11b010  1 0>,		\
	<DCC_READ 0x11b014  1 0>,		\
	<DCC_READ 0x11b018  1 0>,		\
	<DCC_READ 0x11b01c  1 0>,		\
	<DCC_READ 0x11b020  1 0>,		\
	<DCC_READ 0x11b024  1 0>,		\
	<DCC_READ 0x11b028  1 0>,		\
	<DCC_READ 0x11b02c  1 0>,		\
	<DCC_READ 0x11b030  1 0>,		\
	<DCC_READ 0x11b03c  1 0>,		\
	<DCC_READ 0x11b040  1 0>,		\
	<DCC_READ 0x11c000  1 0>,		\
	<DCC_READ 0x11c004  1 0>,		\
	<DCC_READ 0x11c008  1 0>,		\
	<DCC_READ 0x11c00c  1 0>,		\
	<DCC_READ 0x11c010  1 0>,		\
	<DCC_READ 0x11c014  1 0>,		\
	<DCC_READ 0x11c018  1 0>,		\
	<DCC_READ 0x11c01c  1 0>,		\
	<DCC_READ 0x11c020  1 0>,		\
	<DCC_READ 0x11c024  1 0>,		\
	<DCC_READ 0x11c028  1 0>,		\
	<DCC_READ 0x11c02c  1 0>,		\
	<DCC_READ 0x11c030  1 0>,		\
	<DCC_READ 0x11c03c  1 0>,		\
	<DCC_READ 0x11c040  1 0>,		\
	<DCC_READ 0x11d000  1 0>,		\
	<DCC_READ 0x11d004  1 0>,		\
	<DCC_READ 0x11d008  1 0>,		\
	<DCC_READ 0x11d00c  1 0>,		\
	<DCC_READ 0x11d010  1 0>,		\
	<DCC_READ 0x11d014  1 0>,		\
	<DCC_READ 0x11d018  1 0>,		\
	<DCC_READ 0x11d01c  1 0>,		\
	<DCC_READ 0x11d020  1 0>,		\
	<DCC_READ 0x11d024  1 0>,		\
	<DCC_READ 0x11d028  1 0>,		\
	<DCC_READ 0x11d02c  1 0>,		\
	<DCC_READ 0x11d030  1 0>,		\
	<DCC_READ 0x11d03c  1 0>,		\
	<DCC_READ 0x11d040  1 0>,		\
	<DCC_READ 0x120004  1 0>,		\
	<DCC_READ 0x123020  1 0>,		\
	<DCC_READ 0x127004  1 0>,		\
	<DCC_READ 0x135000  1 0>,		\
	<DCC_READ 0x13500c  1 0>,		\
	<DCC_READ 0x135010  1 0>,		\
	<DCC_READ 0x141024  1 0>,		\
	<DCC_READ 0x14401c  1 0>,		\
	<DCC_READ 0x144164  1 0>,		\
	<DCC_READ 0x144284  1 0>,		\
	<DCC_READ 0x1442a0  1 0>,		\
	<DCC_READ 0x1443d0  1 0>,		\
	<DCC_READ 0x145000  1 0>,		\
	<DCC_READ 0x145004  1 0>,		\
	<DCC_READ 0x145008  1 0>,		\
	<DCC_READ 0x145010  1 0>,		\
	<DCC_READ 0x145018  1 0>,		\
	<DCC_READ 0x145044  1 0>,		\
	<DCC_READ 0x145378  1 0>,		\
	<DCC_READ 0x14537c  1 0>,		\
	<DCC_READ 0x145380  1 0>,		\
	<DCC_READ 0x145384  1 0>,		\
	<DCC_READ 0x145398  1 0>,		\
	<DCC_READ 0x147000  1 0>,		\
	<DCC_READ 0x14700c  1 0>,		\
	<DCC_READ 0x147014  1 0>,		\
	<DCC_READ 0x148064  1 0>,		\
	<DCC_READ 0x17100c  1 0>,		\
	<DCC_READ 0x171010  1 0>,		\
	<DCC_READ 0x171018  1 0>,		\
	<DCC_READ 0x171250  1 0>,		\
	<DCC_READ 0x174000  1 0>,		\
	<DCC_READ 0x174004  1 0>,		\
	<DCC_READ 0x174008  1 0>,		\
	<DCC_READ 0x17400c  1 0>,		\
	<DCC_READ 0x174010  1 0>,		\
	<DCC_READ 0x174014  1 0>,		\
	<DCC_READ 0x174018  1 0>,		\
	<DCC_READ 0x17401c  1 0>,		\
	<DCC_READ 0x174020  1 0>,		\
	<DCC_READ 0x174024  1 0>,		\
	<DCC_READ 0x174028  1 0>,		\
	<DCC_READ 0x17402c  1 0>,		\
	<DCC_READ 0x174030  1 0>,		\
	<DCC_READ 0x17403c  1 0>,		\
	<DCC_READ 0x174040  1 0>,		\
	<DCC_READ 0x176000  1 0>,		\
	<DCC_READ 0x176004  1 0>,		\
	<DCC_READ 0x176008  1 0>,		\
	<DCC_READ 0x17600c  1 0>,		\
	<DCC_READ 0x176010  1 0>,		\
	<DCC_READ 0x176014  1 0>,		\
	<DCC_READ 0x176018  1 0>,		\
	<DCC_READ 0x17601c  1 0>,		\
	<DCC_READ 0x176020  1 0>,		\
	<DCC_READ 0x176024  1 0>,		\
	<DCC_READ 0x176028  1 0>,		\
	<DCC_READ 0x17602c  1 0>,		\
	<DCC_READ 0x176030  1 0>,		\
	<DCC_READ 0x17603c  1 0>,		\
	<DCC_READ 0x176040  1 0>,		\
	<DCC_READ 0x178040  1 0>,		\
	<DCC_READ 0x182010  1 0>,		\
	<DCC_READ 0x182884  1 0>,		\
	<DCC_READ 0x182888  1 0>,		\
	<DCC_READ 0x18288c  1 0>,		\
	<DCC_READ 0x182894  1 0>,		\
	<DCC_READ 0x182898  1 0>,		\
	<DCC_READ 0x18289c  1 0>,		\
	<DCC_READ 0x183004  1 0>,		\
	<DCC_READ 0x183008  1 0>,		\
	<DCC_READ 0x18300c  1 0>,		\
	<DCC_READ 0x183024  1 0>,		\
	<DCC_READ 0x183140  1 0>,		\
	<DCC_READ 0x18323c  1 0>,		\
	<DCC_READ 0x189004  1 0>,		\
	<DCC_READ 0x189008  1 0>,		\
	<DCC_READ 0x18900c  1 0>,		\
	<DCC_READ 0x189010  1 0>,		\
	<DCC_READ 0x189014  1 0>,		\
	<DCC_READ 0x189018  1 0>,		\
	<DCC_READ 0x18901c  1 0>,		\
	<DCC_READ 0x189024  1 0>,		\
	<DCC_READ 0x189044  1 0>,		\
	<DCC_READ 0x189164  1 0>,		\
	<DCC_READ 0x190004  1 0>,		\
	<DCC_READ 0x190008  1 0>,		\
	<DCC_READ 0x19000c  1 0>,		\
	<DCC_READ 0x190010  1 0>,		\
	<DCC_READ 0x190014  1 0>,		\
	<DCC_READ 0x190018  1 0>,		\
	<DCC_READ 0x191100  1 0>,		\
	<DCC_READ 0x192100  1 0>,		\
	<DCC_READ 0x193100  1 0>,		\
	<DCC_READ 0x194100  1 0>,		\
	<DCC_READ 0x195100  1 0>,		\
	<DCC_READ 0x196100  1 0>,		\
	<DCC_READ 0x197100  1 0>,		\
	<DCC_READ 0x19b100  1 0>,		\
	<DCC_READ 0x19c100  1 0>,		\
	<DCC_READ 0x3D91078 1 0>,		\
	<DCC_READ 0x3D95000 1 0>,		\
	<DCC_WRITE 0x10B008 0x1 0>

#define config_lito_dcc_pimem \
	<DCC_READ 0x610100 11 0>

#define config_lito_dcc_misc \
	<DCC_READ	0xC2A2040 1 0>

#define config_lito_dcc_ddr			\
	/* DDR -DCC starts here */		\
	/* Start Link list #6 */		\
	/* LLCC */						\
	<DCC_READ 0x9220480 1 0>,		\
	<DCC_READ 0x9232100 1 0>,		\
	<DCC_READ 0x92360b0 1 0>,		\
	<DCC_READ 0x9236044 4 0>,		\
	<DCC_READ 0x923e030 1 0>,		\
	<DCC_READ 0x9241000 1 0>,		\
	<DCC_READ 0x9248048 4 0>,		\
	<DCC_READ 0x9248058 4 0>,		\
	<DCC_READ 0x9236054 1 0>,		\
	<DCC_READ 0x9236040 1 0>,		\
	<DCC_READ 0x923A01C 1 0>,		\
	<DCC_READ 0x92B6054 1 0>,		\
	<DCC_READ 0x92B6040 1 0>,		\
	<DCC_READ 0x92BA01C 1 0>,		\
									\
	/* CABO */						\
	<DCC_READ 0x9260400	1 0>,		\
	<DCC_READ 0x9260410	1 0>,		\
	<DCC_READ 0x9260414	1 0>,		\
	<DCC_READ 0x9260418	1 0>,		\
	<DCC_READ 0x9260420	1 0>,		\
	<DCC_READ 0x9260424	1 0>,		\
	<DCC_READ 0x9260430	1 0>,		\
	<DCC_READ 0x9260440	1 0>,		\
	<DCC_READ 0x9260448	1 0>,		\
	<DCC_READ 0x92604a0	1 0>,		\
	<DCC_READ 0x92604B8	1 0>,		\
	<DCC_READ 0x9265804	1 0>,		\
	<DCC_READ 0x9266418	1 0>,		\
	<DCC_READ 0x92E0400	1 0>,		\
	<DCC_READ 0x92e0410	1 0>,		\
	<DCC_READ 0x92e0414	1 0>,		\
	<DCC_READ 0x92e0418	1 0>,		\
	<DCC_READ 0x92e0420	1 0>,		\
	<DCC_READ 0x92e0424	1 0>,		\
	<DCC_READ 0x92e0430	1 0>,		\
	<DCC_READ 0x92e0440	1 0>,		\
	<DCC_READ 0x92e0448	1 0>,		\
	<DCC_READ 0x92e04a0	1 0>,		\
	<DCC_READ 0x92E04B8	1 0>,		\
	<DCC_READ 0x92E5804	1 0>,		\
	<DCC_READ 0x92E6418	1 0>,		\
									\
	/* LLCC Broadcast */			\
	<DCC_READ	0x9600000	1 0>,	\
	<DCC_READ	0x9600004	1 0>,	\
	<DCC_READ	0x9601000	1 0>,	\
	<DCC_READ	0x9601004	1 0>,	\
	<DCC_READ	0x9602000	1 0>,	\
	<DCC_READ	0x9602004	1 0>,	\
	<DCC_READ	0x9603000	1 0>,	\
	<DCC_READ	0x9603004	1 0>,	\
	<DCC_READ	0x9604000	1 0>,	\
	<DCC_READ	0x9604004	1 0>,	\
	<DCC_READ	0x9605000	1 0>,	\
	<DCC_READ	0x9605004	1 0>,	\
	<DCC_READ	0x9606000	1 0>,	\
	<DCC_READ	0x9606004	1 0>,	\
	<DCC_READ	0x9607000	1 0>,	\
	<DCC_READ	0x9607004	1 0>,	\
	<DCC_READ	0x9608000	1 0>,	\
	<DCC_READ	0x9608004	1 0>,	\
	<DCC_READ	0x9609000	1 0>,	\
	<DCC_READ	0x9609004	1 0>,	\
	<DCC_READ	0x960a000	1 0>,	\
	<DCC_READ	0x960a004	1 0>,	\
	<DCC_READ	0x960b000	1 0>,	\
	<DCC_READ	0x960b004	1 0>,	\
	<DCC_READ	0x960c000	1 0>,	\
	<DCC_READ	0x960c004	1 0>,	\
	<DCC_READ	0x960d000	1 0>,	\
	<DCC_READ	0x960d004	1 0>,	\
	<DCC_READ	0x960e000	1 0>,	\
	<DCC_READ	0x960e004	1 0>,	\
	<DCC_READ	0x960f000	1 0>,	\
	<DCC_READ	0x960f004	1 0>,	\
	<DCC_READ	0x9610000	1 0>,	\
	<DCC_READ	0x9610004	1 0>,	\
	<DCC_READ	0x9611000	1 0>,	\
	<DCC_READ	0x9611004	1 0>,	\
	<DCC_READ	0x9612000	1 0>,	\
	<DCC_READ	0x9612004	1 0>,	\
	<DCC_READ	0x9613000	1 0>,	\
	<DCC_READ	0x9613004	1 0>,	\
	<DCC_READ	0x9614000	1 0>,	\
	<DCC_READ	0x9614004	1 0>,	\
	<DCC_READ	0x9615000	1 0>,	\
	<DCC_READ	0x9615004	1 0>,	\
	<DCC_READ	0x9616000	1 0>,	\
	<DCC_READ	0x9616004	1 0>,	\
	<DCC_READ	0x9617000	1 0>,	\
	<DCC_READ	0x9617004	1 0>,	\
	<DCC_READ	0x9618000	1 0>,	\
	<DCC_READ	0x9618004	1 0>,	\
	<DCC_READ	0x9619000	1 0>,	\
	<DCC_READ	0x9619004	1 0>,	\
	<DCC_READ	0x961a000	1 0>,	\
	<DCC_READ	0x961a004	1 0>,	\
	<DCC_READ	0x961b000	1 0>,	\
	<DCC_READ	0x961b004	1 0>,	\
	<DCC_READ	0x961c000	1 0>,	\
	<DCC_READ	0x961c004	1 0>,	\
	<DCC_READ	0x961d000	1 0>,	\
	<DCC_READ	0x961d004	1 0>,	\
	<DCC_READ	0x961e000	1 0>,	\
	<DCC_READ	0x961e004	1 0>,	\
	<DCC_READ	0x961f000	1 0>,	\
	<DCC_READ	0x961f004	1 0>,	\
									\
	/* SHRM / MCCC */				\
	<DCC_READ	0x9050008	1 0>,	\
	<DCC_READ	0x9050068	1 0>,	\
	<DCC_READ	0x9050078	1 0>,	\
	<DCC_READ	0x90b0280	1 0>,	\
	<DCC_READ	0x90b0288	1 0>,	\
	<DCC_READ	0x90b028c	1 0>,	\
	<DCC_READ	0x90b0290	1 0>,	\
	<DCC_READ	0x90b0294	1 0>,	\
	<DCC_READ	0x90b0298	1 0>,	\
	<DCC_READ	0x90b029c	1 0>,	\
	<DCC_READ	0x90b02a0	1 0>,	\
									\
	<DCC_READ	0x90C012C	1 0>,	\
	<DCC_READ	0x90C8040	1 0>,	\
									\
	/* LLCC1 */						\
	<DCC_READ	0x92a0480	1 0>,	\
	<DCC_READ	0x92b2100	1 0>,	\
	<DCC_READ	0x92b6044	1 0>,	\
	<DCC_READ	0x92b6048	1 0>,	\
	<DCC_READ	0x92b604c	1 0>,	\
	<DCC_READ	0x92b6050	1 0>,	\
	<DCC_READ	0x92b60b0	1 0>,	\
	<DCC_READ	0x92be030	1 0>,	\
	<DCC_READ	0x92c1000	1 0>,	\
	<DCC_READ	0x92C8048 4 0>,		\
	<DCC_READ	0x92c8058	1 0>,	\
	<DCC_READ	0x92c805c	1 0>,	\
	<DCC_READ	0x92c8060	1 0>,	\
	<DCC_READ	0x92c8064	1 0>
	
#define	config_lito_dcc_cam			\
	/* Cam CC */					\
	<DCC_READ 0x10B008  1 0>,		\
	<DCC_READ 0xAD0C1C4 1 0>,		\
	<DCC_READ 0xAD0C12C 1 0>,		\
	<DCC_READ 0xAD0C130 1 0>,		\
	<DCC_READ 0xAD0C144 1 0>,		\
	<DCC_READ 0xAD0C148 1 0>

#define config_lito_dcc_rsc_tcs		\
	/* APPS RSC TCS */				\
	<DCC_READ	0x18200d1c 1 0>,	\
	<DCC_READ	0x18200d34 1 0>,	\
	<DCC_READ	0x18200d38 1 0>,	\
	<DCC_READ	0x18200d3c 1 0>,	\
	<DCC_READ	0x18200d48 1 0>,	\
	<DCC_READ	0x18200d4c 1 0>,	\
	<DCC_READ	0x18200d50 1 0>,	\
	<DCC_READ	0x18200d5c 1 0>,	\
	<DCC_READ	0x18200d60 1 0>,	\
	<DCC_READ	0x18200d64 1 0>,	\
	<DCC_READ	0x18200d70 1 0>,	\
	<DCC_READ	0x18200d74 1 0>,	\
	<DCC_READ	0x18200d78 1 0>,	\
	<DCC_READ	0x18200fbc 1 0>,	\
	<DCC_READ	0x1820125c 1 0>,	\
	<DCC_READ	0x182014fc 1 0>,	\
	<DCC_READ	0x1822000c 1 0>,	\
	<DCC_READ	0x18220d00 1 0>,	\
	<DCC_READ	0x18220d04 1 0>,	\
	<DCC_READ	0x18220d14 1 0>,	\
	<DCC_READ	0x18220d18 1 0>,	\
	<DCC_READ	0x18220d1c 1 0>,	\
	<DCC_READ	0x18220fb4 1 0>,	\
	<DCC_READ	0x18220fb8 1 0>,	\
	<DCC_READ	0x18220fbc 1 0>,	\
	<DCC_READ	0x18221254 1 0>,	\
	<DCC_READ	0x18221258 1 0>,	\
	<DCC_READ	0x1822125c 1 0>,	\
	<DCC_READ	0x18221274 1 0>,	\
	<DCC_READ	0x18221278 1 0>,	\
	<DCC_READ	0x18221288 1 0>,	\
	<DCC_READ	0x1822128c 1 0>,	\
	<DCC_READ	0x1822129c 1 0>,	\
	<DCC_READ	0x182212a0 1 0>,	\
	<DCC_READ	0x182212b0 1 0>,	\
	<DCC_READ	0x182212b4 1 0>,	\
	<DCC_READ	0x182212c4 1 0>,	\
	<DCC_READ	0x182212c8 1 0>,	\
	<DCC_READ	0x182212d8 1 0>,	\
	<DCC_READ	0x182212dc 1 0>,	\
	<DCC_READ	0x182212ec 1 0>,	\
	<DCC_READ	0x182212f0 1 0>,	\
	<DCC_READ	0x18221300 1 0>,	\
	<DCC_READ	0x18221304 1 0>,	\
	<DCC_READ	0x18221314 1 0>,	\
	<DCC_READ	0x18221318 1 0>,	\
	<DCC_READ	0x18221328 1 0>,	\
	<DCC_READ	0x1822132c 1 0>,	\
	<DCC_READ	0x1822133c 1 0>,	\
	<DCC_READ	0x18221340 1 0>,	\
	<DCC_READ	0x18221350 1 0>,	\
	<DCC_READ	0x18221354 1 0>,	\
	<DCC_READ	0x18221364 1 0>,	\
	<DCC_READ	0x18221368 1 0>,	\
	<DCC_READ	0x18221378 1 0>,	\
	<DCC_READ	0x1822137c 1 0>,	\
	<DCC_READ	0x1822138c 1 0>,	\
	<DCC_READ	0x18221390 1 0>,	\
	<DCC_READ	0x182213a0 1 0>,	\
	<DCC_READ	0x182213a4 1 0>,	\
	<DCC_READ	0x182214f4 1 0>,	\
	<DCC_READ	0x182214f8 1 0>,	\
	<DCC_READ	0x182214fc 1 0>,	\
	<DCC_READ	0x18221514 1 0>,	\
	<DCC_READ	0x18221518 1 0>,	\
	<DCC_READ	0x18221528 1 0>,	\
	<DCC_READ	0x1822152c 1 0>,	\
	<DCC_READ	0x1822153c 1 0>,	\
	<DCC_READ	0x18221540 1 0>,	\
	<DCC_READ	0x18221550 1 0>,	\
	<DCC_READ	0x18221554 1 0>,	\
	<DCC_READ	0x18221564 1 0>,	\
	<DCC_READ	0x18221568 1 0>,	\
	<DCC_READ	0x18221578 1 0>,	\
	<DCC_READ	0x1822157c 1 0>,	\
	<DCC_READ	0x1822158c 1 0>,	\
	<DCC_READ	0x18221590 1 0>,	\
	<DCC_READ	0x182215a0 1 0>,	\
	<DCC_READ	0x182215a4 1 0>,	\
	<DCC_READ	0x182215b4 1 0>,	\
	<DCC_READ	0x182215b8 1 0>,	\
	<DCC_READ	0x182215c8 1 0>,	\
	<DCC_READ	0x182215cc 1 0>,	\
	<DCC_READ	0x182215dc 1 0>,	\
	<DCC_READ	0x182215e0 1 0>,	\
	<DCC_READ	0x182215f0 1 0>,	\
	<DCC_READ	0x182215f4 1 0>,	\
	<DCC_READ	0x18221604 1 0>,	\
	<DCC_READ	0x18221608 1 0>,	\
	<DCC_READ	0x18221618 1 0>,	\
	<DCC_READ	0x1822161c 1 0>,	\
	<DCC_READ	0x1822162c 1 0>,	\
	<DCC_READ	0x18221630 1 0>,	\
	<DCC_READ	0x18221640 1 0>,	\
	<DCC_READ	0x18221644 1 0>,	\
	<DCC_READ	0x18221794 1 0>,	\
	<DCC_READ	0x18221798 1 0>,	\
	<DCC_READ	0x1822179c 1 0>,	\
	<DCC_READ	0x182217b4 1 0>,	\
	<DCC_READ	0x182217b8 1 0>,	\
	<DCC_READ	0x182217c8 1 0>,	\
	<DCC_READ	0x182217cc 1 0>,	\
	<DCC_READ	0x182217dc 1 0>,	\
	<DCC_READ	0x182217e0 1 0>,	\
	<DCC_READ	0x182217f0 1 0>,	\
	<DCC_READ	0x182217f4 1 0>,	\
	<DCC_READ	0x18221804 1 0>,	\
	<DCC_READ	0x18221808 1 0>,	\
	<DCC_READ	0x18221818 1 0>,	\
	<DCC_READ	0x1822181c 1 0>,	\
	<DCC_READ	0x1822182c 1 0>,	\
	<DCC_READ	0x18221830 1 0>,	\
	<DCC_READ	0x18221840 1 0>,	\
	<DCC_READ	0x18221844 1 0>,	\
	<DCC_READ	0x18221854 1 0>,	\
	<DCC_READ	0x18221858 1 0>,	\
	<DCC_READ	0x18221868 1 0>,	\
	<DCC_READ	0x1822186c 1 0>,	\
	<DCC_READ	0x1822187c 1 0>,	\
	<DCC_READ	0x18221880 1 0>,	\
	<DCC_READ	0x18221890 1 0>,	\
	<DCC_READ	0x18221894 1 0>,	\
	<DCC_READ	0x182218a4 1 0>,	\
	<DCC_READ	0x182218a8 1 0>,	\
	<DCC_READ	0x182218b8 1 0>,	\
	<DCC_READ	0x182218bc 1 0>,	\
	<DCC_READ	0x182218cc 1 0>,	\
	<DCC_READ	0x182218d0 1 0>,	\
	<DCC_READ	0x182218e0 1 0>,	\
	<DCC_READ	0x182218e4 1 0>,	\
	<DCC_READ	0x18221a34 1 0>,	\
	<DCC_READ	0x18221a38 1 0>,	\
	<DCC_READ	0x18221a3c 1 0>,	\
	<DCC_READ	0x18221a54 1 0>,	\
	<DCC_READ	0x18221a58 1 0>,	\
	<DCC_READ	0x18221a68 1 0>,	\
	<DCC_READ	0x18221a6c 1 0>,	\
	<DCC_READ	0x18221a7c 1 0>,	\
	<DCC_READ	0x18221a80 1 0>,	\
	<DCC_READ	0x18221a90 1 0>,	\
	<DCC_READ	0x18221a94 1 0>,	\
	<DCC_READ	0x18221aa4 1 0>,	\
	<DCC_READ	0x18221aa8 1 0>,	\
	<DCC_READ	0x18221ab8 1 0>,	\
	<DCC_READ	0x18221abc 1 0>,	\
	<DCC_READ	0x18221acc 1 0>,	\
	<DCC_READ	0x18221ad0 1 0>,	\
	<DCC_READ	0x18221ae0 1 0>,	\
	<DCC_READ	0x18221ae4 1 0>,	\
	<DCC_READ	0x18221af4 1 0>,	\
	<DCC_READ	0x18221af8 1 0>,	\
	<DCC_READ	0x18221b08 1 0>,	\
	<DCC_READ	0x18221b0c 1 0>,	\
	<DCC_READ	0x18221b1c 1 0>,	\
	<DCC_READ	0x18221b20 1 0>,	\
	<DCC_READ	0x18221b30 1 0>,	\
	<DCC_READ	0x18221b34 1 0>,	\
	<DCC_READ	0x18221b44 1 0>,	\
	<DCC_READ	0x18221b48 1 0>,	\
	<DCC_READ	0x18221b58 1 0>,	\
	<DCC_READ	0x18221b5c 1 0>,	\
	<DCC_READ	0x18221b6c 1 0>,	\
	<DCC_READ	0x18221b70 1 0>,	\
	<DCC_READ	0x18221b80 1 0>,	\
	<DCC_READ	0x18221b84 1 0>,	\
	<DCC_READ	0x18221cd4 1 0>,	\
	<DCC_READ	0x18221cd8 1 0>,	\
	<DCC_READ	0x18221cdc 1 0>,	\
	<DCC_READ	0x18221cf4 1 0>,	\
	<DCC_READ	0x18221cf8 1 0>,	\
	<DCC_READ	0x18221d08 1 0>,	\
	<DCC_READ	0x18221d0c 1 0>,	\
	<DCC_READ	0x18221d1c 1 0>,	\
	<DCC_READ	0x18221d20 1 0>,	\
	<DCC_READ	0x18221d30 1 0>,	\
	<DCC_READ	0x18221d34 1 0>,	\
	<DCC_READ	0x18221d44 1 0>,	\
	<DCC_READ	0x18221d48 1 0>,	\
	<DCC_READ	0x18221d58 1 0>,	\
	<DCC_READ	0x18221d5c 1 0>,	\
	<DCC_READ	0x18221d6c 1 0>,	\
	<DCC_READ	0x18221d70 1 0>,	\
	<DCC_READ	0x18221d80 1 0>,	\
	<DCC_READ	0x18221d84 1 0>,	\
	<DCC_READ	0x18221d94 1 0>,	\
	<DCC_READ	0x18221d98 1 0>,	\
	<DCC_READ	0x18221da8 1 0>,	\
	<DCC_READ	0x18221dac 1 0>,	\
	<DCC_READ	0x18221dbc 1 0>,	\
	<DCC_READ	0x18221dc0 1 0>,	\
	<DCC_READ	0x18221dd0 1 0>,	\
	<DCC_READ	0x18221dd4 1 0>,	\
	<DCC_READ	0x18221de4 1 0>,	\
	<DCC_READ	0x18221de8 1 0>,	\
	<DCC_READ	0x18221df8 1 0>,	\
	<DCC_READ	0x18221dfc 1 0>,	\
	<DCC_READ	0x18221e0c 1 0>,	\
	<DCC_READ	0x18221e10 1 0>,	\
	<DCC_READ	0x18221e20 1 0>,	\
	<DCC_READ	0x18221e24 1 0>,	\
	<DCC_READ	0x18221f74 1 0>,	\
	<DCC_READ	0x18221f78 1 0>,	\
	<DCC_READ	0x18221f7c 1 0>,	\
	<DCC_READ	0x18221f94 1 0>,	\
	<DCC_READ	0x18221f98 1 0>,	\
	<DCC_READ	0x18221fa8 1 0>,	\
	<DCC_READ	0x18221fac 1 0>,	\
	<DCC_READ	0x18221fbc 1 0>,	\
	<DCC_READ	0x18221fc0 1 0>,	\
	<DCC_READ	0x18221fd0 1 0>,	\
	<DCC_READ	0x18221fd4 1 0>,	\
	<DCC_READ	0x18221fe4 1 0>,	\
	<DCC_READ	0x18221fe8 1 0>,	\
	<DCC_READ	0x18221ff8 1 0>,	\
	<DCC_READ	0x18221ffc 1 0>,	\
	<DCC_READ	0x1822200c 1 0>,	\
	<DCC_READ	0x18222010 1 0>,	\
	<DCC_READ	0x18222020 1 0>,	\
	<DCC_READ	0x18222024 1 0>,	\
	<DCC_READ	0x18222034 1 0>,	\
	<DCC_READ	0x18222038 1 0>,	\
	<DCC_READ	0x18222048 1 0>,	\
	<DCC_READ	0x1822204c 1 0>,	\
	<DCC_READ	0x1822205c 1 0>,	\
	<DCC_READ	0x18222060 1 0>,	\
	<DCC_READ	0x18222070 1 0>,	\
	<DCC_READ	0x18222074 1 0>,	\
	<DCC_READ	0x18222084 1 0>,	\
	<DCC_READ	0x18222088 1 0>,	\
	<DCC_READ	0x18222098 1 0>,	\
	<DCC_READ	0x1822209c 1 0>,	\
	<DCC_READ	0x182220ac 1 0>,	\
	<DCC_READ	0x182220b0 1 0>,	\
	<DCC_READ	0x182220c0 1 0>,	\
	<DCC_READ	0x182220c4 1 0>,	\
									\
	/* NPU RSC */					\
									\
	/* CDSP RSCp */					\
	<DCC_READ 0x80a4010 1 0>,		\
	<DCC_READ 0x80a4014 1 0>,		\
	<DCC_READ 0x80a4018 1 0>,		\
	<DCC_READ 0x80a4030 1 0>,		\
	<DCC_READ 0x80a4038 1 0>,		\
	<DCC_READ 0x80a4040 1 0>,		\
	<DCC_READ 0x80a4048 1 0>,		\
	<DCC_READ 0x80a40d0 1 0>,		\
	<DCC_READ 0x80a4208 1 0>,		\
	<DCC_READ 0x80a420c 1 0>,		\
	<DCC_READ 0x80a4210 1 0>,		\
	<DCC_READ 0x80a4228 1 0>,		\
	<DCC_READ 0x80a422c 1 0>,		\
	<DCC_READ 0x80a4230 1 0>,		\
	<DCC_READ 0x80a4248 1 0>,		\
	<DCC_READ 0x80a424c 1 0>,		\
	<DCC_READ 0x80a4250 1 0>,		\
	<DCC_READ 0x80a4268 1 0>,		\
	<DCC_READ 0x80a426c 1 0>,		\
	<DCC_READ 0x80a4270 1 0>,		\
	<DCC_READ 0x80a4288 1 0>,		\
	<DCC_READ 0x80a428c 1 0>,		\
	<DCC_READ 0x80a4290 1 0>,		\
	<DCC_READ 0x80a42a8 1 0>,		\
	<DCC_READ 0x80a42ac 1 0>,		\
	<DCC_READ 0x80a42b0 1 0>,		\
	<DCC_READ 0x80a4400 1 0>,		\
	<DCC_READ 0x80a4404 1 0>,		\
	<DCC_READ 0x80a4408 1 0>,		\
	<DCC_READ 0x80a4d04 1 0>,		\
									\
	/* QDSP6 RSC */					\
	<DCC_READ 0x83b0010	1 0>,		\
	<DCC_READ 0x83b0014	1 0>,		\
	<DCC_READ 0x83b0018	1 0>,		\
	<DCC_READ 0x83b0208	1 0>,		\
	<DCC_READ 0x83b020c	1 0>,		\
	<DCC_READ 0x83b0210	1 0>,		\
	<DCC_READ 0x83b0228	1 0>,		\
	<DCC_READ 0x83b022c	1 0>,		\
	<DCC_READ 0x83b0230	1 0>,		\
	<DCC_READ 0x83b0248	1 0>,		\
	<DCC_READ 0x83b024c	1 0>,		\
	<DCC_READ 0x83b0250	1 0>,		\
	<DCC_READ 0x83b0268	1 0>,		\
	<DCC_READ 0x83b026c	1 0>,		\
	<DCC_READ 0x83b0270	1 0>,		\
	<DCC_READ 0x83b0288	1 0>,		\
	<DCC_READ 0x83b028c	1 0>,		\
	<DCC_READ 0x83b0290	1 0>,		\
	<DCC_READ 0x83b02a8	1 0>,		\
	<DCC_READ 0x83b02ac	1 0>,		\
	<DCC_READ 0x83b02b0	1 0>,		\
	<DCC_READ 0x83b0400	1 0>,		\
	<DCC_READ 0x83b0404	1 0>,		\
	<DCC_READ 0x83b0408	1 0>,		\
									\
	/* CDSP PDC */					\
	<DCC_READ 0xb2b0010 1 0>,		\
	<DCC_READ 0xb2b0900 1 0>,		\
	<DCC_READ	0xb2b1020 1 0>,		\
	<DCC_READ	0xb2b1024 1 0>,		\
	<DCC_READ	0xb2b1030 1 0>,		\
	<DCC_READ	0xb2b103c 1 0>,		\
	<DCC_READ	0xb2b1200 1 0>,		\
	<DCC_READ	0xb2b1204 1 0>,		\
	<DCC_READ	0xb2b1208 1 0>,		\
	<DCC_READ	0xb2b1214 1 0>,		\
	<DCC_READ	0xb2b1218 1 0>,		\
	<DCC_READ	0xb2b121c 1 0>,		\
	<DCC_READ	0xb2b1228 1 0>,		\
	<DCC_READ	0xb2b122c 1 0>,		\
	<DCC_READ	0xb2b1230 1 0>,		\
	<DCC_READ	0xb2b123c 1 0>,		\
	<DCC_READ	0xb2b1240 1 0>,		\
	<DCC_READ	0xb2b1244 1 0>,		\
	<DCC_READ	0xb2b1250 1 0>,		\
	<DCC_READ	0xb2b1254 1 0>,		\
	<DCC_READ	0xb2b1258 1 0>,		\
	<DCC_READ	0xb2b4510 1 0>,		\
	<DCC_READ	0xb2b4514 1 0>,		\
	<DCC_READ	0xb2b4520 1 0>,		\
									\
	/* QDSP6 General */				\
	<DCC_READ	0x8300044 1 0>,		\
	<DCC_READ	0x8300468 1 0>,		\
	<DCC_READ	0x8302000 1 0>,		\
	<DCC_READ	0x8302028 1 0>,		\
	<DCC_READ	0x8390380 32 0>

#define config_lito_dcc_lpass_rsc	\
	/* LPASS RSC */					\
	<DCC_READ	0x3500010	1 0>,	\
	<DCC_READ	0x3500014	1 0>,	\
	<DCC_READ	0x3500018	1 0>,	\
	<DCC_READ	0x3500030	1 0>,	\
	<DCC_READ	0x3500038	1 0>,	\
	<DCC_READ	0x3500040	1 0>,	\
	<DCC_READ	0x3500048	1 0>,	\
	<DCC_READ	0x35000d0	1 0>,	\
	<DCC_READ	0x3500208	1 0>,	\
	<DCC_READ	0x350020c	1 0>,	\
	<DCC_READ	0x3500210	1 0>,	\
	<DCC_READ	0x3500228	1 0>,	\
	<DCC_READ	0x350022c	1 0>,	\
	<DCC_READ	0x3500230	1 0>,	\
	<DCC_READ	0x3500248	1 0>,	\
	<DCC_READ	0x350024c	1 0>,	\
	<DCC_READ	0x3500250	1 0>,	\
	<DCC_READ	0x3500268	1 0>,	\
	<DCC_READ	0x350026c	1 0>,	\
	<DCC_READ	0x3500270	1 0>,	\
	<DCC_READ	0x3500288	1 0>,	\
	<DCC_READ	0x350028c	1 0>,	\
	<DCC_READ	0x3500290	1 0>,	\
	<DCC_READ	0x35002a8	1 0>,	\
	<DCC_READ	0x35002ac	1 0>,	\
	<DCC_READ	0x35002b0	1 0>,	\
	<DCC_READ	0x3500400	1 0>,	\
	<DCC_READ	0x3500404	1 0>,	\
	<DCC_READ	0x3500408	1 0>,	\
	<DCC_READ	0x3500d04	1 0>,	\
									\
	/* LPASS RSCc */				\
	<DCC_READ	0x30b0010 1 0>,		\
	<DCC_READ	0x30b0014 1 0>,		\
	<DCC_READ	0x30b0018 1 0>,		\
	<DCC_READ	0x30b0208 1 0>,		\
	<DCC_READ	0x30b020c 1 0>,		\
	<DCC_READ	0x30b0210 1 0>,		\
	<DCC_READ	0x30b0228 1 0>,		\
	<DCC_READ	0x30b022c 1 0>,		\
	<DCC_READ	0x30b0230 1 0>,		\
	<DCC_READ	0x30b0248 1 0>,		\
	<DCC_READ	0x30b024c 1 0>,		\
	<DCC_READ	0x30b0250 1 0>,		\
	<DCC_READ	0x30b0268 1 0>,		\
	<DCC_READ	0x30b026c 1 0>,		\
	<DCC_READ	0x30b0270 1 0>,		\
	<DCC_READ	0x30b0288 1 0>,		\
	<DCC_READ	0x30b028c 1 0>,		\
	<DCC_READ	0x30b0290 1 0>,		\
	<DCC_READ	0x30b02a8 1 0>,		\
	<DCC_READ	0x30b02ac 1 0>,		\
	<DCC_READ	0x30b02b0 1 0>,		\
	<DCC_READ	0x30b0400 1 0>,		\
	<DCC_READ	0x30b0404 1 0>,		\
	<DCC_READ	0x30b0408 1 0>,		\
									\
	/* Audio PDC */					\
	<DCC_READ	0xb250010 1 0>,		\
	<DCC_READ	0xb250014 1 0>,		\
	<DCC_READ	0xb250900 1 0>,		\
	<DCC_READ	0xb250904 1 0>,		\
	<DCC_READ	0xb251020 1 0>,		\
	<DCC_READ	0xb251024 1 0>,		\
	<DCC_READ	0xb251030 1 0>,		\
	<DCC_READ	0xb25103c 1 0>,		\
	<DCC_READ	0xb251200 1 0>,		\
	<DCC_READ	0xb251204 1 0>,		\
	<DCC_READ	0xb251208 1 0>,		\
	<DCC_READ	0xb251214 1 0>,		\
	<DCC_READ	0xb251218 1 0>,		\
	<DCC_READ	0xb25121c 1 0>,		\
	<DCC_READ	0xb251228 1 0>,		\
	<DCC_READ	0xb25122c 1 0>,		\
	<DCC_READ	0xb251230 1 0>,		\
	<DCC_READ	0xb25123c 1 0>,		\
	<DCC_READ	0xb251240 1 0>,		\
	<DCC_READ	0xb251244 1 0>,		\
	<DCC_READ	0xb251250 1 0>,		\
	<DCC_READ	0xb251254 1 0>,		\
	<DCC_READ	0xb251258 1 0>,		\
	<DCC_READ	0xb254510 1 0>,		\
	<DCC_READ	0xb254514 1 0>,		\
	<DCC_READ	0xb254520 1 0>,		\
									\
	/* LPASS General */				\
	<DCC_READ	0x3000044	1 0>,	\
	<DCC_READ	0x3000468	1 0>,	\
	<DCC_READ	0x3002000	1 0>,	\
	<DCC_READ	0x3002004	1 0>,	\
	<DCC_READ	0x3002028	1 0>,	\
	<DCC_READ	0x3090380 32 0>,	\
									\
	/* WDOG */						\
	<DCC_READ	0x8384004 5 0>,		\
	<DCC_READ	0x8300304 1 0>

#define config_lito_dcc_mss_rsc 	\
	/* MSS RSCp */					\
	<DCC_READ 0x4200010	1 0>,		\
	<DCC_READ 0x4200014	1 0>,		\
	<DCC_READ 0x4200018	1 0>,		\
	<DCC_READ 0x4200030	1 0>,		\
	<DCC_READ 0x4200034	1 0>,		\
	<DCC_READ 0x4200038	1 0>,		\
	<DCC_READ 0x420003c	1 0>,		\
	<DCC_READ 0x4200040	1 0>,		\
	<DCC_READ 0x4200044	1 0>,		\
	<DCC_READ 0x4200048	1 0>,		\
	<DCC_READ 0x42000d0	1 0>,		\
	<DCC_READ 0x42000d8	1 0>,		\
	<DCC_READ 0x4200100	1 0>,		\
	<DCC_READ 0x4200208	1 0>,		\
	<DCC_READ 0x420020c	1 0>,		\
	<DCC_READ 0x4200210	1 0>,		\
	<DCC_READ 0x4200228	1 0>,		\
	<DCC_READ 0x420022c	1 0>,		\
	<DCC_READ 0x4200230	1 0>,		\
	<DCC_READ 0x4200248	1 0>,		\
	<DCC_READ 0x420024c	1 0>,		\
	<DCC_READ 0x4200250	1 0>,		\
	<DCC_READ 0x4200268	1 0>,		\
	<DCC_READ 0x420026c	1 0>,		\
	<DCC_READ 0x4200270	1 0>,		\
	<DCC_READ 0x4200288	1 0>,		\
	<DCC_READ 0x420028c	1 0>,		\
	<DCC_READ 0x4200290	1 0>,		\
	<DCC_READ 0x42002a8	1 0>,		\
	<DCC_READ 0x42002ac	1 0>,		\
	<DCC_READ 0x42002b0	1 0>,		\
	<DCC_READ 0x4200400	1 0>,		\
	<DCC_READ 0x4200404	1 0>,		\
	<DCC_READ 0x4200408	1 0>,		\
	<DCC_READ 0x4200d00	1 0>,		\
	<DCC_READ 0x4200d04	1 0>,		\
									\
	/* MSS RSCc */					\
	<DCC_READ	0x4130010	1 0>,	\
	<DCC_READ	0x4130014	1 0>,	\
	<DCC_READ	0x4130018	1 0>,	\
	<DCC_READ	0x41300d0	1 0>,	\
	<DCC_READ	0x41300d8	1 0>,	\
	<DCC_READ	0x4130100	1 0>,	\
	<DCC_READ	0x4130104	1 0>,	\
	<DCC_READ	0x4130208	1 0>,	\
	<DCC_READ	0x413020c	1 0>,	\
	<DCC_READ	0x4130210	1 0>,	\
	<DCC_READ	0x4130228	1 0>,	\
	<DCC_READ	0x413022c	1 0>,	\
	<DCC_READ	0x4130230	1 0>,	\
	<DCC_READ	0x4130248	1 0>,	\
	<DCC_READ	0x413024c	1 0>,	\
	<DCC_READ	0x4130250	1 0>,	\
	<DCC_READ	0x4130268	1 0>,	\
	<DCC_READ	0x413026c	1 0>,	\
	<DCC_READ	0x4130270	1 0>,	\
	<DCC_READ	0x4130288	1 0>,	\
	<DCC_READ	0x413028c	1 0>,	\
	<DCC_READ	0x4130290	1 0>,	\
	<DCC_READ	0x41302a8	1 0>,	\
	<DCC_READ	0x41302ac	1 0>,	\
	<DCC_READ	0x41302b0	1 0>,	\
	<DCC_READ	0x4130400	1 0>,	\
	<DCC_READ	0x4130404	1 0>,	\
	<DCC_READ	0x4130408	1 0>,	\
									\
	/* MSS PDC */					\
	<DCC_READ	0xb2c0010	1 0>,	\
	<DCC_READ	0xb2c0014	1 0>,	\
	<DCC_READ	0xb2c0900	1 0>,	\
	<DCC_READ	0xb2c0904	1 0>,	\
	<DCC_READ	0xb2c1020	1 0>,	\
	<DCC_READ	0xb2c1024	1 0>,	\
	<DCC_READ	0xb2c1030	1 0>,	\
	<DCC_READ	0xb2c1200	1 0>,	\
	<DCC_READ	0xb2c1204	1 0>,	\
	<DCC_READ	0xb2c1208	1 0>,	\
	<DCC_READ	0xb2c1214	1 0>,	\
	<DCC_READ	0xb2c1218	1 0>,	\
	<DCC_READ	0xb2c121c	1 0>,	\
	<DCC_READ	0xb2c1228	1 0>,	\
	<DCC_READ	0xb2c122c	1 0>,	\
	<DCC_READ	0xb2c1230	1 0>,	\
	<DCC_READ	0xb2c123c	1 0>,	\
	<DCC_READ	0xb2c1240	1 0>,	\
	<DCC_READ	0xb2c1244	1 0>,	\
	<DCC_READ	0xb2c1250	1 0>,	\
	<DCC_READ	0xb2c1254	1 0>,	\
	<DCC_READ	0xb2c1258	1 0>,	\
	<DCC_READ	0xb2c4510	1 0>,	\
	<DCC_READ	0xb2c4514	1 0>,	\
	<DCC_READ	0xb2c4520	1 0>,	\
									\
	/* MSS RSCC TCS */				\
	<DCC_READ	0x4201000 1 0>,		\
	<DCC_READ	0x4202000 1 0>,		\
	<DCC_READ	0x4201004 1 0>,		\
	<DCC_READ	0x4202ac8 1 0>,		\
	<DCC_READ	0x4201808 1 0>,		\
	<DCC_READ	0x4201aac 1 0>,		\
	<DCC_READ	0x420000c 1 0>,		\
	<DCC_READ	0x4200ffc 1 0>,		\
	<DCC_READ	0x420203c 1 0>,		\
	<DCC_READ	0x4201010 1 0>,		\
	<DCC_READ	0x4202d58 1 0>,		\
	<DCC_READ	0x4200fb8 1 0>,		\
	<DCC_READ	0x4201014 1 0>,		\
	<DCC_READ	0x4201ff8 1 0>,		\
	<DCC_READ	0x4201018 1 0>,		\
	<DCC_READ	0x4201804 1 0>,		\
	<DCC_READ	0x420181c 1 0>,		\
	<DCC_READ	0x4201820 1 0>,		\
	<DCC_READ	0x42012b0 1 0>,		\
	<DCC_READ	0x4201024 1 0>,		\
	<DCC_READ	0x4201028 1 0>,		\
	<DCC_READ	0x4201d5c 1 0>,		\
	<DCC_READ	0x420102c 1 0>,		\
	<DCC_READ	0x4201830 1 0>,		\
	<DCC_READ	0x4202808 1 0>,		\
	<DCC_READ	0x4201834 1 0>,		\
	<DCC_READ	0x4203038 1 0>,		\
	<DCC_READ	0x4202ab4 1 0>,		\
	<DCC_READ	0x420103c 1 0>,		\
	<DCC_READ	0x4201840 1 0>,		\
	<DCC_READ	0x4202560 1 0>,		\
	<DCC_READ	0x4200d98 1 0>,		\
	<DCC_READ	0x4201844 1 0>,		\
	<DCC_READ	0x4201848 1 0>,		\
	<DCC_READ	0x420180c 1 0>,		\
	<DCC_READ	0x4202880 1 0>,		\
	<DCC_READ	0x420104c 1 0>,		\
	<DCC_READ	0x4201050 1 0>,		\
	<DCC_READ	0x42012b8 1 0>,		\
	<DCC_READ	0x42017b8 1 0>,		\
	<DCC_READ	0x4201854 1 0>,		\
	<DCC_READ	0x4201858 1 0>,		\
	<DCC_READ	0x4201564 1 0>,		\
	<DCC_READ	0x420185c 1 0>,		\
	<DCC_READ	0x4201060 1 0>,		\
	<DCC_READ	0x4202010 1 0>,		\
	<DCC_READ	0x4201064 1 0>,		\
	<DCC_READ	0x4201068 1 0>,		\
	<DCC_READ	0x4201abc 1 0>,		\
	<DCC_READ	0x420186c 1 0>,		\
	<DCC_READ	0x4201870 1 0>,		\
	<DCC_READ	0x4202d68 1 0>,		\
	<DCC_READ	0x4201074 1 0>,		\
	<DCC_READ	0x4201620 1 0>,		\
	<DCC_READ	0x4201078 1 0>,		\
	<DCC_READ	0x4202014 1 0>,		\
	<DCC_READ	0x420107c 1 0>,		\
	<DCC_READ	0x4201b30 1 0>,		\
	<DCC_READ	0x4201880 1 0>,		\
	<DCC_READ	0x4201ac0 1 0>,		\
	<DCC_READ	0x4202084 1 0>,		\
	<DCC_READ	0x4201884 1 0>,		\
	<DCC_READ	0x4201088 1 0>,		\
	<DCC_READ	0x420156c 1 0>,		\
	<DCC_READ	0x4200fbc 1 0>,		\
	<DCC_READ	0x420108c 1 0>,		\
	<DCC_READ	0x4201090 1 0>,		\
	<DCC_READ	0x4201818 1 0>,		\
	<DCC_READ	0x4201894 1 0>,		\
	<DCC_READ	0x4201898 1 0>,		\
	<DCC_READ	0x42012c4 1 0>,		\
	<DCC_READ	0x420109c 1 0>,		\
	<DCC_READ	0x42010a0 1 0>,		\
	<DCC_READ	0x4202d70 1 0>,		\
	<DCC_READ	0x42018a4 1 0>,		\
	<DCC_READ	0x42018a8 1 0>,		\
	<DCC_READ	0x420281c 1 0>,		\
	<DCC_READ	0x42018ac 1 0>,		\
	<DCC_READ	0x42010b0 1 0>,		\
	<DCC_READ	0x42012c8 1 0>,		\
	<DCC_READ	0x42010b4 1 0>,		\
	<DCC_READ	0x42018b8 1 0>,		\
	<DCC_READ	0x4201d74 1 0>,		\
	<DCC_READ	0x42018bc 1 0>,		\
	<DCC_READ	0x42012f0 1 0>,		\
	<DCC_READ	0x42018c0 1 0>,		\
	<DCC_READ	0x4202020 1 0>,		\
	<DCC_READ	0x42010c4 1 0>,		\
	<DCC_READ	0x4200d14 1 0>,		\
	<DCC_READ	0x42010c8 1 0>,		\
	<DCC_READ	0x4202acc 1 0>,		\
	<DCC_READ	0x42017bc 1 0>,		\
	<DCC_READ	0x42010cc 1 0>,		\
	<DCC_READ	0x42018d0 1 0>,		\
	<DCC_READ	0x4202578 1 0>,		\
	<DCC_READ	0x42018d4 1 0>,		\
	<DCC_READ	0x42010d8 1 0>,		\
	<DCC_READ	0x4202024 1 0>,		\
	<DCC_READ	0x42010dc 1 0>,		\
	<DCC_READ	0x42010e0 1 0>,		\
	<DCC_READ	0x4201ad0 1 0>,		\
	<DCC_READ	0x42018e4 1 0>,		\
	<DCC_READ	0x42018e8 1 0>,		\
	<DCC_READ	0x420157c 1 0>,		\
	<DCC_READ	0x42010ec 1 0>,		\
	<DCC_READ	0x42010f0 1 0>,		\
	<DCC_READ	0x4202028 1 0>,		\
	<DCC_READ	0x42010f4 1 0>,		\
	<DCC_READ	0x42015e0 1 0>,		\
	<DCC_READ	0x4201ad4 1 0>,		\
	<DCC_READ	0x4201100 1 0>,		\
	<DCC_READ	0x4201580 1 0>,		\
	<DCC_READ	0x4201104 1 0>,		\
	<DCC_READ	0x4201108 1 0>,		\
	<DCC_READ	0x420182c 1 0>,		\
	<DCC_READ	0x42012d8 1 0>,		\
	<DCC_READ	0x4201d84 1 0>,		\
	<DCC_READ	0x4202830 1 0>,		\
	<DCC_READ	0x42012dc 1 0>,		\
	<DCC_READ	0x4201d88 1 0>,		\
	<DCC_READ	0x4202034 1 0>,		\
	<DCC_READ	0x4201d9c 1 0>,		\
	<DCC_READ	0x4200d18 1 0>,		\
	<DCC_READ	0x4202844 1 0>,		\
	<DCC_READ	0x4201ae0 1 0>,		\
	<DCC_READ	0x4202800 1 0>,		\
	<DCC_READ	0x420158c 1 0>,		\
	<DCC_READ	0x4201038 1 0>,		\
	<DCC_READ	0x4201ae4 1 0>,		\
	<DCC_READ	0x4202590 1 0>,		\
	<DCC_READ	0x420283c 1 0>,		\
	<DCC_READ	0x42015e4 1 0>,		\
	<DCC_READ	0x4201ae8 1 0>,		\
	<DCC_READ	0x420208c 1 0>,		\
	<DCC_READ	0x42015a0 1 0>,		\
	<DCC_READ	0x4201af4 1 0>,		\
	<DCC_READ	0x4201594 1 0>,		\
	<DCC_READ	0x4201d94 1 0>,		\
	<DCC_READ	0x4201518 1 0>,		\
	<DCC_READ	0x4201040 1 0>,		\
	<DCC_READ	0x4202754 1 0>,		\
	<DCC_READ	0x42012ec 1 0>,		\
	<DCC_READ	0x4201d98 1 0>,		\
	<DCC_READ	0x4203044 1 0>,		\
	<DCC_READ	0x42022f0 1 0>,		\
	<DCC_READ	0x4200de8 1 0>,		\
	<DCC_READ	0x4200d9c 1 0>,		\
	<DCC_READ	0x4201890 1 0>,		\
	<DCC_READ	0x4202048 1 0>,		\
	<DCC_READ	0x42012b4 1 0>,		\
	<DCC_READ	0x4200d1c 1 0>,		\
	<DCC_READ	0x4202af4 1 0>,		\
	<DCC_READ	0x4202804 1 0>,		\
	<DCC_READ	0x42025a0 1 0>,		\
	<DCC_READ	0x420204c 1 0>,		\
	<DCC_READ	0x4201af8 1 0>,		\
	<DCC_READ	0x4202da4 1 0>,		\
	<DCC_READ	0x4202050 1 0>,		\
	<DCC_READ	0x4201afc 1 0>,		\
	<DCC_READ	0x42015a4 1 0>,		\
	<DCC_READ	0x4202da8 1 0>,		\
	<DCC_READ	0x42029f4 1 0>,		\
	<DCC_READ	0x4203048 1 0>,		\
	<DCC_READ	0x4201054 1 0>,		\
	<DCC_READ	0x4202b40 1 0>,		\
	<DCC_READ	0x42029fc 1 0>,		\
	<DCC_READ	0x4201300 1 0>,		\
	<DCC_READ	0x4201fc4 1 0>,		\
	<DCC_READ	0x4202dac 1 0>,		\
	<DCC_READ	0x4202858 1 0>,		\
	<DCC_READ	0x4202214 1 0>,		\
	<DCC_READ	0x4202a18 1 0>,		\
	<DCC_READ	0x4201304 1 0>,		\
	<DCC_READ	0x420221c 1 0>,		\
	<DCC_READ	0x4200dec 1 0>,		\
	<DCC_READ	0x42025b0 1 0>,		\
	<DCC_READ	0x4202a28 1 0>,		\
	<DCC_READ	0x420205c 1 0>,		\
	<DCC_READ	0x4202a2c 1 0>,		\
	<DCC_READ	0x4202a30 1 0>,		\
	<DCC_READ	0x4201308 1 0>,		\
	<DCC_READ	0x4201a34 1 0>,		\
	<DCC_READ	0x4201d1c 1 0>,		\
	<DCC_READ	0x4201a38 1 0>,		\
	<DCC_READ	0x42025b4 1 0>,		\
	<DCC_READ	0x4201a3c 1 0>,		\
	<DCC_READ	0x4202a40 1 0>,		\
	<DCC_READ	0x4202060 1 0>,		\
	<DCC_READ	0x4202a44 1 0>,		\
	<DCC_READ	0x4202248 1 0>,		\
	<DCC_READ	0x4201b0c 1 0>,		\
	<DCC_READ	0x420224c 1 0>,		\
	<DCC_READ	0x4202250 1 0>,		\
	<DCC_READ	0x4202db8 1 0>,		\
	<DCC_READ	0x4201254 1 0>,		\
	<DCC_READ	0x4201258 1 0>,		\
	<DCC_READ	0x4202864 1 0>,		\
	<DCC_READ	0x4201a5c 1 0>,		\
	<DCC_READ	0x4202260 1 0>,		\
	<DCC_READ	0x4201b10 1 0>,		\
	<DCC_READ	0x4202264 1 0>,		\
	<DCC_READ	0x4201a68 1 0>,		\
	<DCC_READ	0x4202dbc 1 0>,		\
	<DCC_READ	0x4201a6c 1 0>,		\
	<DCC_READ	0x420200c 1 0>,		\
	<DCC_READ	0x4201a70 1 0>,		\
	<DCC_READ	0x4201868 1 0>,		\
	<DCC_READ	0x42015dc 1 0>,		\
	<DCC_READ	0x4201274 1 0>,		\
	<DCC_READ	0x4203008 1 0>,		\
	<DCC_READ	0x4202a78 1 0>,		\
	<DCC_READ	0x4201314 1 0>,		\
	<DCC_READ	0x4201a7c 1 0>,		\
	<DCC_READ	0x4201a80 1 0>,		\
	<DCC_READ	0x4200dc0 1 0>,		\
	<DCC_READ	0x4201a84 1 0>,		\
	<DCC_READ	0x4201288 1 0>,		\
	<DCC_READ	0x420286c 1 0>,		\
	<DCC_READ	0x420128c 1 0>,		\
	<DCC_READ	0x4201290 1 0>,		\
	<DCC_READ	0x4201318 1 0>,		\
	<DCC_READ	0x4201a94 1 0>,		\
	<DCC_READ	0x4201a98 1 0>,		\
	<DCC_READ	0x4200dc4 1 0>,		\
	<DCC_READ	0x420129c 1 0>,		\
	<DCC_READ	0x4202aa0 1 0>,		\
	<DCC_READ	0x4203070 1 0>,		\
	<DCC_READ	0x4201da8 1 0>,		\
	<DCC_READ	0x4202aa4 1 0>,		\
	<DCC_READ	0x4201aa8 1 0>,		\
	<DCC_READ	0x4201b1c 1 0>,		\
	<DCC_READ	0x42022ac 1 0>,		\
	<DCC_READ	0x42022b0 1 0>,		\
	<DCC_READ	0x42015c8 1 0>,		\
	<DCC_READ	0x42022b4 1 0>,		\
	<DCC_READ	0x4201ab8 1 0>,		\
	<DCC_READ	0x4202074 1 0>,		\
	<DCC_READ	0x4202abc 1 0>,		\
	<DCC_READ	0x42022c0 1 0>,		\
	<DCC_READ	0x4201b20 1 0>,		\
	<DCC_READ	0x42022c4 1 0>,		\
	<DCC_READ	0x42022c8 1 0>,		\
	<DCC_READ	0x4202dcc 1 0>,		\
	<DCC_READ	0x4201acc 1 0>,		\
	<DCC_READ	0x4202ad0 1 0>,		\
	<DCC_READ	0x4202078 1 0>,		\
	<DCC_READ	0x42022d4 1 0>,		\
	<DCC_READ	0x42015f0 1 0>,		\
	<DCC_READ	0x42022d8 1 0>,		\
	<DCC_READ	0x4201b24 1 0>,		\
	<DCC_READ	0x42022dc 1 0>,		\
	<DCC_READ	0x42012e0 1 0>,		\
	<DCC_READ	0x4201dd0 1 0>,		\
	<DCC_READ	0x4202ae4 1 0>,		\
	<DCC_READ	0x42022e8 1 0>,		\
	<DCC_READ	0x420187c 1 0>,		\
	<DCC_READ	0x4202ab8 1 0>,		\
	<DCC_READ	0x42022ec 1 0>,		\
	<DCC_READ	0x420300c 1 0>,		\
	<DCC_READ	0x4202af0 1 0>,		\
	<DCC_READ	0x4201328 1 0>,		\
	<DCC_READ	0x42012f4 1 0>,		\
	<DCC_READ	0x4202af8 1 0>,		\
	<DCC_READ	0x4201dd4 1 0>,		\
	<DCC_READ	0x42022fc 1 0>,		\
	<DCC_READ	0x4201d60 1 0>,		\
	<DCC_READ	0x4202300 1 0>,		\
	<DCC_READ	0x4203080 1 0>,		\
	<DCC_READ	0x4202304 1 0>,		\
	<DCC_READ	0x4201b08 1 0>,		\
	<DCC_READ	0x420232c 1 0>,		\
	<DCC_READ	0x4202b0c 1 0>,		\
	<DCC_READ	0x4202310 1 0>,		\
	<DCC_READ	0x4201dd8 1 0>,		\
	<DCC_READ	0x4202314 1 0>,		\
	<DCC_READ	0x4202318 1 0>,		\
	<DCC_READ	0x4203084 1 0>,		\
	<DCC_READ	0x4201dac 1 0>,		\
	<DCC_READ	0x420131c 1 0>,		\
	<DCC_READ	0x4202b20 1 0>,		\
	<DCC_READ	0x4201330 1 0>,		\
	<DCC_READ	0x4202324 1 0>,		\
	<DCC_READ	0x4202328 1 0>,		\
	<DCC_READ	0x4200ddc 1 0>,		\
	<DCC_READ	0x4202b2c 1 0>,		\
	<DCC_READ	0x4202b30 1 0>,		\
	<DCC_READ	0x4202088 1 0>,		\
	<DCC_READ	0x4201b34 1 0>,		\
	<DCC_READ	0x4201b38 1 0>,		\
	<DCC_READ	0x4202b34 1 0>,		\
	<DCC_READ	0x420133c 1 0>,		\
	<DCC_READ	0x4201340 1 0>,		\
	<DCC_READ	0x42025e0 1 0>,		\
	<DCC_READ	0x4202b44 1 0>,		\
	<DCC_READ	0x4201b48 1 0>,		\
	<DCC_READ	0x420288c 1 0>,		\
	<DCC_READ	0x4201b4c 1 0>,		\
	<DCC_READ	0x4201350 1 0>,		\
	<DCC_READ	0x4202338 1 0>,		\
	<DCC_READ	0x4201354 1 0>,		\
	<DCC_READ	0x4201358 1 0>,		\
	<DCC_READ	0x4201de4 1 0>,		\
	<DCC_READ	0x4201b5c 1 0>,		\
	<DCC_READ	0x4201b60 1 0>,		\
	<DCC_READ	0x4202890 1 0>,		\
	<DCC_READ	0x4201364 1 0>,		\
	<DCC_READ	0x4203010 1 0>,		\
	<DCC_READ	0x4201368 1 0>,		\
	<DCC_READ	0x420233c 1 0>,		\
	<DCC_READ	0x4201b6c 1 0>,		\
	<DCC_READ	0x4201b70 1 0>,		\
	<DCC_READ	0x4201de8 1 0>,		\
	<DCC_READ	0x4201b74 1 0>,		\
	<DCC_READ	0x4201378 1 0>,		\
	<DCC_READ	0x4202894 1 0>,		\
	<DCC_READ	0x420137c 1 0>,		\
	<DCC_READ	0x4201380 1 0>,		\
	<DCC_READ	0x4202340 1 0>,		\
	<DCC_READ	0x4201b84 1 0>,		\
	<DCC_READ	0x4201b88 1 0>,		\
	<DCC_READ	0x4201dec 1 0>,		\
	<DCC_READ	0x4200db4 1 0>,		\
	<DCC_READ	0x420138c 1 0>,		\
	<DCC_READ	0x4201390 1 0>,		\
	<DCC_READ	0x4202098 1 0>,		\
	<DCC_READ	0x4201db0 1 0>,		\
	<DCC_READ	0x4201394 1 0>,		\
	<DCC_READ	0x4201b44 1 0>,		\
	<DCC_READ	0x4202814 1 0>,		\
	<DCC_READ	0x42013a0 1 0>,		\
	<DCC_READ	0x4200df0 1 0>,		\
	<DCC_READ	0x42013a4 1 0>,		\
	<DCC_READ	0x4200d50 1 0>,		\
	<DCC_READ	0x42013a8 1 0>,		\
	<DCC_READ	0x420209c 1 0>,		\
	<DCC_READ	0x4202b48 1 0>,		\
	<DCC_READ	0x42015f4 1 0>,		\
	<DCC_READ	0x42020a0 1 0>,		\
	<DCC_READ	0x42015f8 1 0>,		\
	<DCC_READ	0x420234c 1 0>,		\
	<DCC_READ	0x42029f8 1 0>,		\
	<DCC_READ	0x4200fd8 1 0>,		\
	<DCC_READ	0x4202b04 1 0>,		\
	<DCC_READ	0x4203058 1 0>,		\
	<DCC_READ	0x42010a4 1 0>,		\
	<DCC_READ	0x4202758 1 0>,		\
	<DCC_READ	0x4202350 1 0>,		\
	<DCC_READ	0x4200dfc 1 0>,		\
	<DCC_READ	0x42028a8 1 0>,		\
	<DCC_READ	0x4202840 1 0>,		\
	<DCC_READ	0x4202354 1 0>,		\
	<DCC_READ	0x4202600 1 0>,		\
	<DCC_READ	0x42020ac 1 0>,		\
	<DCC_READ	0x42028a0 1 0>,		\
	<DCC_READ	0x4201b58 1 0>,		\
	<DCC_READ	0x4202818 1 0>,		\
	<DCC_READ	0x4202604 1 0>,		\
	<DCC_READ	0x4201794 1 0>,		\
	<DCC_READ	0x420223c 1 0>,		\
	<DCC_READ	0x42020b0 1 0>,		\
	<DCC_READ	0x420275c 1 0>,		\
	<DCC_READ	0x4201608 1 0>,		\
	<DCC_READ	0x42020b4 1 0>,		\
	<DCC_READ	0x420304c 1 0>,		\
	<DCC_READ	0x4202360 1 0>,		\
	<DCC_READ	0x42015b8 1 0>,		\
	<DCC_READ	0x420160c 1 0>,		\
	<DCC_READ	0x4202b08 1 0>,		\
	<DCC_READ	0x4201530 1 0>,		\
	<DCC_READ	0x420305c 1 0>,		\
	<DCC_READ	0x42010b8 1 0>,		\
	<DCC_READ	0x420252c 1 0>,		\
	<DCC_READ	0x4202364 1 0>,		\
	<DCC_READ	0x4201d70 1 0>,		\
	<DCC_READ	0x4200e10 1 0>,		\
	<DCC_READ	0x42024bc 1 0>,		\
	<DCC_READ	0x4202368 1 0>,		\
	<DCC_READ	0x4200e00 1 0>,		\
	<DCC_READ	0x4200e14 1 0>,		\
	<DCC_READ	0x42020c0 1 0>,		\
	<DCC_READ	0x42028a4 1 0>,		\
	<DCC_READ	0x42012cc 1 0>,		\
	<DCC_READ	0x4200d34 1 0>,		\
	<DCC_READ	0x420136c 1 0>,		\
	<DCC_READ	0x42017dc 1 0>,		\
	<DCC_READ	0x4201d30 1 0>,		\
	<DCC_READ	0x4202218 1 0>,		\
	<DCC_READ	0x4201798 1 0>,		\
	<DCC_READ	0x4202c94 1 0>,		\
	<DCC_READ	0x4202c98 1 0>,		\
	<DCC_READ	0x42020c4 1 0>,		\
	<DCC_READ	0x4202c9c 1 0>,		\
	<DCC_READ	0x4202a1c 1 0>,		\
	<DCC_READ	0x42020c8 1 0>,		\
	<DCC_READ	0x42024b4 1 0>,		\
	<DCC_READ	0x42024b8 1 0>,		\
	<DCC_READ	0x4201f74 1 0>,		\
	<DCC_READ	0x42015bc 1 0>,		\
	<DCC_READ	0x4202cbc 1 0>,		\
	<DCC_READ	0x4202064 1 0>,		\
	<DCC_READ	0x4202cc8 1 0>,		\
	<DCC_READ	0x42018cc 1 0>,		\
	<DCC_READ	0x4202ccc 1 0>,		\
	<DCC_READ	0x420301c 1 0>,		\
	<DCC_READ	0x4202cd0 1 0>,		\
	<DCC_READ	0x4201f78 1 0>,		\
	<DCC_READ	0x4201cd4 1 0>,		\
	<DCC_READ	0x4201cd8 1 0>,		\
	<DCC_READ	0x4200e24 1 0>,		\
	<DCC_READ	0x4201cdc 1 0>,		\
	<DCC_READ	0x4202ce0 1 0>,		\
	<DCC_READ	0x4202ce4 1 0>,		\
	<DCC_READ	0x42024e8 1 0>,		\
	<DCC_READ	0x420277c 1 0>,		\
	<DCC_READ	0x42024ec 1 0>,		\
	<DCC_READ	0x4200e04 1 0>,		\
	<DCC_READ	0x42024f0 1 0>,		\
	<DCC_READ	0x4200e28 1 0>,		\
	<DCC_READ	0x4201cf4 1 0>,		\
	<DCC_READ	0x4201cf8 1 0>,		\
	<DCC_READ	0x42024d4 1 0>,		\
	<DCC_READ	0x4201cfc 1 0>,		\
	<DCC_READ	0x4201344 1 0>,		\
	<DCC_READ	0x4202500 1 0>,		\
	<DCC_READ	0x4201b80 1 0>,		\
	<DCC_READ	0x4202504 1 0>,		\
	<DCC_READ	0x42017e0 1 0>,		\
	<DCC_READ	0x4201558 1 0>,		\
	<DCC_READ	0x4201d08 1 0>,		\
	<DCC_READ	0x4200e2c 1 0>,		\
	<DCC_READ	0x420179c 1 0>,		\
	<DCC_READ	0x4201d0c 1 0>,		\
	<DCC_READ	0x4201d10 1 0>,		\
	<DCC_READ	0x42024d8 1 0>,		\
	<DCC_READ	0x4202514 1 0>,		\
	<DCC_READ	0x4202518 1 0>,		\
	<DCC_READ	0x420151c 1 0>,		\
	<DCC_READ	0x4201d20 1 0>,		\
	<DCC_READ	0x4201d24 1 0>,		\
	<DCC_READ	0x4201528 1 0>,		\
	<DCC_READ	0x42024dc 1 0>,		\
	<DCC_READ	0x4202d2c 1 0>,		\
	<DCC_READ	0x4202d30 1 0>,		\
	<DCC_READ	0x4202554 1 0>,		\
	<DCC_READ	0x4201d34 1 0>,		\
	<DCC_READ	0x4200d38 1 0>,		\
	<DCC_READ	0x4202234 1 0>,		\
	<DCC_READ	0x4200fd4 1 0>,		\
	<DCC_READ	0x4200d3c 1 0>,		\
	<DCC_READ	0x4201540 1 0>,		\
	<DCC_READ	0x42018e0 1 0>,		\
	<DCC_READ	0x4201544 1 0>,		\
	<DCC_READ	0x4203020 1 0>,		\
	<DCC_READ	0x4201d48 1 0>,		\
	<DCC_READ	0x420254c 1 0>,		\
	<DCC_READ	0x4202550 1 0>,		\
	<DCC_READ	0x4202238 1 0>,		\
	<DCC_READ	0x4202850 1 0>,		\
	<DCC_READ	0x4202d54 1 0>,		\
	<DCC_READ	0x4201d58 1 0>,		\
	<DCC_READ	0x4200d5c 1 0>,		\
	<DCC_READ	0x4200d60 1 0>,		\
	<DCC_READ	0x4202790 1 0>,		\
	<DCC_READ	0x42017cc 1 0>,		\
	<DCC_READ	0x4200d64 1 0>,		\
	<DCC_READ	0x4202568 1 0>,		\
	<DCC_READ	0x4202a3c 1 0>,		\
	<DCC_READ	0x4201d6c 1 0>,		\
	<DCC_READ	0x4200d70 1 0>,		\
	<DCC_READ	0x4200d74 1 0>,		\
	<DCC_READ	0x4200d78 1 0>,		\
	<DCC_READ	0x4201f94 1 0>,		\
	<DCC_READ	0x420257c 1 0>,		\
	<DCC_READ	0x42017e4 1 0>,		\
	<DCC_READ	0x4201d38 1 0>,		\
	<DCC_READ	0x4201d80 1 0>,		\
	<DCC_READ	0x4200e40 1 0>,		\
	<DCC_READ	0x420228c 1 0>,		\
	<DCC_READ	0x4200d84 1 0>,		\
	<DCC_READ	0x42027e0 1 0>,		\
	<DCC_READ	0x4200d88 1 0>,		\
	<DCC_READ	0x4200d8c 1 0>,		\
	<DCC_READ	0x4202d90 1 0>,		\
	<DCC_READ	0x4201f98 1 0>,		\
	<DCC_READ	0x4202d94 1 0>,		\
	<DCC_READ	0x4202d98 1 0>,		\
	<DCC_READ	0x420259c 1 0>,		\
	<DCC_READ	0x4200da0 1 0>,		\
	<DCC_READ	0x4202cf0 1 0>,		\
	<DCC_READ	0x42025a4 1 0>,		\
	<DCC_READ	0x42015a8 1 0>,		\
	<DCC_READ	0x4201f9c 1 0>,		\
	<DCC_READ	0x4200dac 1 0>,		\
	<DCC_READ	0x4200db0 1 0>,		\
	<DCC_READ	0x42015b4 1 0>,		\
	<DCC_READ	0x4200fe8 1 0>,		\
	<DCC_READ	0x420153c 1 0>,		\
	<DCC_READ	0x42025b8 1 0>,		\
	<DCC_READ	0x42014f4 1 0>,		\
	<DCC_READ	0x4201a90 1 0>,		\
	<DCC_READ	0x4201dbc 1 0>,		\
	<DCC_READ	0x4201fe4 1 0>,		\
	<DCC_READ	0x4203024 1 0>,		\
	<DCC_READ	0x4201dc0 1 0>,		\
	<DCC_READ	0x4201dc4 1 0>,		\
	<DCC_READ	0x4200dc8 1 0>,		\
	<DCC_READ	0x42025cc 1 0>,		\
	<DCC_READ	0x4202dd0 1 0>,		\
	<DCC_READ	0x42014f8 1 0>,		\
	<DCC_READ	0x4202dd4 1 0>,		\
	<DCC_READ	0x42025d8 1 0>,		\
	<DCC_READ	0x42027a4 1 0>,		\
	<DCC_READ	0x42025dc 1 0>,		\
	<DCC_READ	0x4202de0 1 0>,		\
	<DCC_READ	0x4202a50 1 0>,		\
	<DCC_READ	0x4202de4 1 0>,		\
	<DCC_READ	0x4202de8 1 0>,		\
	<DCC_READ	0x42014fc 1 0>,		\
	<DCC_READ	0x42025ec 1 0>,		\
	<DCC_READ	0x42025f0 1 0>,		\
	<DCC_READ	0x4201fa8 1 0>,		\
	<DCC_READ	0x42025f4 1 0>,		\
	<DCC_READ	0x4202828 1 0>,		\
	<DCC_READ	0x4201df8 1 0>,		\
	<DCC_READ	0x4202d7c 1 0>,		\
	<DCC_READ	0x4201dfc 1 0>,		\
	<DCC_READ	0x4201e00 1 0>,		\
	<DCC_READ	0x4201604 1 0>,		\
	<DCC_READ	0x4202cf4 1 0>,		\
	<DCC_READ	0x4202608 1 0>,		\
	<DCC_READ	0x4201fac 1 0>,		\
	<DCC_READ	0x4201e0c 1 0>,		\
	<DCC_READ	0x4201e10 1 0>,		\
	<DCC_READ	0x4201a58 1 0>,		\
	<DCC_READ	0x4201e14 1 0>,		\
	<DCC_READ	0x4201618 1 0>,		\
	<DCC_READ	0x4202d04 1 0>,		\
	<DCC_READ	0x420161c 1 0>,		\
	<DCC_READ	0x4201e20 1 0>,		\
	<DCC_READ	0x4201fb0 1 0>,		\
	<DCC_READ	0x4201e24 1 0>,		\
	<DCC_READ	0x4201e28 1 0>,		\
	<DCC_READ	0x4202070 1 0>,		\
	<DCC_READ	0x420162c 1 0>,		\
	<DCC_READ	0x4200fec 1 0>,		\
	<DCC_READ	0x4202b18 1 0>,		\
	<DCC_READ	0x4201630 1 0>,		\
	<DCC_READ	0x4202d08 1 0>,		\
	<DCC_READ	0x4201634 1 0>,		\
	<DCC_READ	0x4200e38 1 0>,		\
	<DCC_READ	0x42017b4 1 0>,		\
	<DCC_READ	0x4202dc0 1 0>,		\
	<DCC_READ	0x4200e3c 1 0>,		\
	<DCC_READ	0x4201640 1 0>,		\
	<DCC_READ	0x4201644 1 0>,		\
	<DCC_READ	0x4201648 1 0>,		\
	<DCC_READ	0x4202d0c 1 0>,		\
	<DCC_READ	0x4200e4c 1 0>,		\
	<DCC_READ	0x4200e50 1 0>,		\
	<DCC_READ	0x4202fb8 1 0>,		\
	<DCC_READ	0x4202a58 1 0>,		\
	<DCC_READ	0x4200e54 1 0>,		\
	<DCC_READ	0x4202a64 1 0>,		\
	<DCC_READ	0x4200e60 1 0>,		\
	<DCC_READ	0x4202510 1 0>,		\
	<DCC_READ	0x4200e64 1 0>,		\
	<DCC_READ	0x4200e68 1 0>,		\
	<DCC_READ	0x4202fbc 1 0>,		\
	<DCC_READ	0x4201568 1 0>,		\
	<DCC_READ	0x420282c 1 0>,		\
	<DCC_READ	0x4202a68 1 0>,		\
	<DCC_READ	0x4202d80 1 0>,		\
	<DCC_READ	0x4201514 1 0>,		\
	<DCC_READ	0x4202cf8 1 0>,		\
	<DCC_READ	0x4201fc0 1 0>,		\
	<DCC_READ	0x4202cb4 1 0>,		\
	<DCC_READ	0x4202a6c 1 0>,		\
	<DCC_READ	0x4202d18 1 0>,		\
	<DCC_READ	0x4202564 1 0>,		\
	<DCC_READ	0x42027c4 1 0>,		\
	<DCC_READ	0x42015cc 1 0>,		\
	<DCC_READ	0x4202270 1 0>,		\
	<DCC_READ	0x42025c8 1 0>,		\
	<DCC_READ	0x4202b1c 1 0>,		\
	<DCC_READ	0x4202d1c 1 0>,		\
	<DCC_READ	0x4201a54 1 0>,		\
	<DCC_READ	0x42017c8 1 0>,		\
	<DCC_READ	0x42024fc 1 0>,		\
	<DCC_READ	0x4202274 1 0>,		\
	<DCC_READ	0x4202d20 1 0>,		\
	<DCC_READ	0x4201d4c 1 0>,		\
	<DCC_READ	0x42027cc 1 0>,		\
	<DCC_READ	0x4201278 1 0>,		\
	<DCC_READ	0x4202524 1 0>,		\
	<DCC_READ	0x4200d48 1 0>,		\
	<DCC_READ	0x4201fd0 1 0>,		\
	<DCC_READ	0x42017f0 1 0>,		\
	<DCC_READ	0x42025c4 1 0>,		\
	<DCC_READ	0x4201d44 1 0>,		\
	<DCC_READ	0x4202a7c 1 0>,		\
	<DCC_READ	0x4202d84 1 0>,		\
	<DCC_READ	0x4202d6c 1 0>,		\
	<DCC_READ	0x4202528 1 0>,		\
	<DCC_READ	0x4201fd4 1 0>,		\
	<DCC_READ	0x4202cb8 1 0>,		\
	<DCC_READ	0x4202a80 1 0>,		\
	<DCC_READ	0x420306c 1 0>,		\
	<DCC_READ	0x420152c 1 0>,		\
	<DCC_READ	0x4201fd8 1 0>,		\
	<DCC_READ	0x42015d0 1 0>,		\
	<DCC_READ	0x4202284 1 0>,		\
	<DCC_READ	0x4203074 1 0>,		\
	<DCC_READ	0x4202588 1 0>,		\
	<DCC_READ	0x4202adc 1 0>,		\
	<DCC_READ	0x4203030 1 0>,		\
	<DCC_READ	0x4200fdc 1 0>,		\
	<DCC_READ	0x4202a54 1 0>,		\
	<DCC_READ	0x4202288 1 0>,		\
	<DCC_READ	0x4202f34 1 0>,		\
	<DCC_READ	0x4202f38 1 0>,		\
	<DCC_READ	0x4202d34 1 0>,		\
	<DCC_READ	0x4202f3c 1 0>,		\
	<DCC_READ	0x4202868 1 0>,		\
	<DCC_READ	0x4202fe0 1 0>,		\
	<DCC_READ	0x4200e18 1 0>,		\
	<DCC_READ	0x4202a8c 1 0>,		\
	<DCC_READ	0x4200dd4 1 0>,		\
	<DCC_READ	0x4202538 1 0>,		\
	<DCC_READ	0x4202f54 1 0>,		\
	<DCC_READ	0x4202f58 1 0>,		\
	<DCC_READ	0x4202878 1 0>,		\
	<DCC_READ	0x4202f5c 1 0>,		\
	<DCC_READ	0x42017f4 1 0>,		\
	<DCC_READ	0x420125c 1 0>,		\
	<DCC_READ	0x4202a90 1 0>,		\
	<DCC_READ	0x4202f68 1 0>,		\
	<DCC_READ	0x420253c 1 0>,		\
	<DCC_READ	0x4202f6c 1 0>,		\
	<DCC_READ	0x4203088 1 0>,		\
	<DCC_READ	0x4202f70 1 0>,		\
	<DCC_READ	0x4201fe8 1 0>,		\
	<DCC_READ	0x4202774 1 0>,		\
	<DCC_READ	0x4202778 1 0>,		\
	<DCC_READ	0x4202a94 1 0>,		\
	<DCC_READ	0x4202cdc 1 0>,		\
	<DCC_READ	0x4202f7c 1 0>,		\
	<DCC_READ	0x4202f80 1 0>,		\
	<DCC_READ	0x4202d40 1 0>,		\
	<DCC_READ	0x4202f84 1 0>,		\
	<DCC_READ	0x4202788 1 0>,		\
	<DCC_READ	0x4201fec 1 0>,		\
	<DCC_READ	0x420278c 1 0>,		\
	<DCC_READ	0x4202f90 1 0>,		\
	<DCC_READ	0x4202298 1 0>,		\
	<DCC_READ	0x4201590 1 0>,		\
	<DCC_READ	0x4202f94 1 0>,		\
	<DCC_READ	0x4202038 1 0>,		\
	<DCC_READ	0x4202f98 1 0>,		\
	<DCC_READ	0x4202d44 1 0>,		\
	<DCC_READ	0x420258c 1 0>,		\
	<DCC_READ	0x4200fb4 1 0>,		\
	<DCC_READ	0x420279c 1 0>,		\
	<DCC_READ	0x4202ae0 1 0>,		\
	<DCC_READ	0x4203034 1 0>,		\
	<DCC_READ	0x42027a0 1 0>,		\
	<DCC_READ	0x4200ff0 1 0>,		\
	<DCC_READ	0x4202540 1 0>,		\
	<DCC_READ	0x4202fa4 1 0>,		\
	<DCC_READ	0x4202fa8 1 0>,		\
	<DCC_READ	0x420229c 1 0>,		\
	<DCC_READ	0x420127c 1 0>,		\
	<DCC_READ	0x4202854 1 0>,		\
	<DCC_READ	0x4202fac 1 0>,		\
	<DCC_READ	0x4202a14 1 0>,		\
	<DCC_READ	0x42027b0 1 0>,		\
	<DCC_READ	0x4202d48 1 0>,		\
	<DCC_READ	0x42027b4 1 0>,		\
	<DCC_READ	0x4201f7c 1 0>,		\
	<DCC_READ	0x42027b8 1 0>,		\
	<DCC_READ	0x42027f4 1 0>,		\
	<DCC_READ	0x42017d0 1 0>,		\
	<DCC_READ	0x4201fbc 1 0>,		\
	<DCC_READ	0x4202fc0 1 0>,		\
	<DCC_READ	0x42012a0 1 0>,		\
	<DCC_READ	0x4200dd8 1 0>,		\
	<DCC_READ	0x420132c 1 0>,		\
	<DCC_READ	0x42027c8 1 0>,		\
	<DCC_READ	0x4200d4c 1 0>,		\
	<DCC_READ	0x4201578 1 0>,		\
	<DCC_READ	0x4202fcc 1 0>,		\
	<DCC_READ	0x4202fd0 1 0>,		\
	<DCC_READ	0x420287c 1 0>,		\
	<DCC_READ	0x42012a4 1 0>,		\
	<DCC_READ	0x4202fd4 1 0>,		\
	<DCC_READ	0x42017f8 1 0>,		\
	<DCC_READ	0x4202278 1 0>,		\
	<DCC_READ	0x42027d8 1 0>,		\
	<DCC_READ	0x4201aa4 1 0>,		\
	<DCC_READ	0x42022a0 1 0>,		\
	<DCC_READ	0x42027dc 1 0>,		\
	<DCC_READ	0x420225c 1 0>,		\
	<DCC_READ	0x4201550 1 0>,		\
	<DCC_READ	0x4202fe4 1 0>,		\
	<DCC_READ	0x4202fe8 1 0>,		\
	<DCC_READ	0x4201ffc 1 0>,		\
	<DCC_READ	0x42027ec 1 0>,		\
	<DCC_READ	0x42027f0 1 0>,		\
	<DCC_READ	0x4202aa8 1 0>,		\
	<DCC_READ	0x4202ff4 1 0>,		\
	<DCC_READ	0x4202d5c 1 0>,		\
	<DCC_READ	0x4202574 1 0>,		\
	<DCC_READ	0x4202ff8 1 0>,		\
	<DCC_READ	0x4201554 1 0>,		\
	<DCC_READ	0x4203060 1 0>,		\
	<DCC_READ	0x4202ffc 1 0>,		\
									\
	/* MSS General */				\
	<DCC_READ	0x018a004	1 0>,	\
	<DCC_READ	0x4080044	1 0>,	\
	<DCC_READ	0x40800b0	1 0>,	\
	<DCC_READ	0x4080304	1 0>,	\
	<DCC_READ	0x4080438	1 0>,	\
	<DCC_READ	0x4080448	1 0>,	\
	<DCC_READ	0x4080468	1 0>,	\
	<DCC_READ	0x4082000	1 0>,	\
	<DCC_READ	0x4082004	1 0>,	\
	<DCC_READ	0x4082028	1 0>,	\
	<DCC_READ	0x4110380 32 0>,	\
	<DCC_READ	0x41a802c	1 0>,	\
	<DCC_READ	0x4402028	1 0>

#define config_lito_dcc_l3_rsc		\
	<DCC_READ	0x182300d0 1 0>,	\
	<DCC_READ	0x182300d8 1 0>,	\
	<DCC_READ	0x18230100 1 0>,	\
	<DCC_READ	0x18230400 1 0>,	\
	<DCC_READ	0x18230404 1 0>,	\
	<DCC_READ	0x18230408 1 0>,	\
	<DCC_READ	0x18230460 1 0>,	\
	<DCC_READ	0x18230464 1 0>,	\
	<DCC_READ	0x18230d00 1 0>,	\
	<DCC_READ	0x18230d04 1 0>,	\
	<DCC_READ	0x18230d10 1 0>,	\
	<DCC_READ	0x18230d14 1 0>,	\
	<DCC_READ	0x18230d18 1 0>,	\
	<DCC_READ	0x18230d1c 1 0>,	\
	<DCC_READ	0x18230d34 1 0>,	\
	<DCC_READ	0x18230d38 1 0>,	\
	<DCC_READ	0x18230d3c 1 0>,	\
	<DCC_READ	0x18230d48 1 0>,	\
	<DCC_READ	0x18230d4c 1 0>,	\
	<DCC_READ	0x18230d50 1 0>,	\
	<DCC_READ	0x18230d5c 1 0>,	\
	<DCC_READ	0x18230d60 1 0>,	\
	<DCC_READ	0x18230d64 1 0>,	\
	<DCC_READ	0x18230d70 1 0>,	\
	<DCC_READ	0x18230d74 1 0>,	\
	<DCC_READ	0x18230d78 1 0>,	\
	<DCC_READ	0x18230d84 1 0>,	\
	<DCC_READ	0x18230d88 1 0>,	\
	<DCC_READ	0x18230d8c 1 0>,	\
	<DCC_READ	0x18230d98 1 0>,	\
	<DCC_READ	0x18230d9c 1 0>,	\
	<DCC_READ	0x18230da0 1 0>,	\
	<DCC_READ	0x18230dac 1 0>,	\
	<DCC_READ	0x18230db0 1 0>,	\
	<DCC_READ	0x18230db4 1 0>,	\
	<DCC_READ	0x18230dc0 1 0>,	\
	<DCC_READ	0x18230dc4 1 0>,	\
	<DCC_READ	0x18230dc8 1 0>,	\
	<DCC_READ	0x18230dd4 1 0>,	\
	<DCC_READ	0x18230dd8 1 0>,	\
	<DCC_READ	0x18230ddc 1 0>,	\
	<DCC_READ	0x18230de8 1 0>,	\
	<DCC_READ	0x18230dec 1 0>,	\
	<DCC_READ	0x18230df0 1 0>,	\
	<DCC_READ	0x18230dfc 1 0>,	\
	<DCC_READ	0x18230e00 1 0>,	\
	<DCC_READ	0x18230e04 1 0>,	\
	<DCC_READ	0x18230e10 1 0>,	\
	<DCC_READ	0x18230e14 1 0>,	\
	<DCC_READ	0x18230e18 1 0>,	\
	<DCC_READ	0x18230e24 1 0>,	\
	<DCC_READ	0x18230e28 1 0>,	\
	<DCC_READ	0x18230e2c 1 0>,	\
	<DCC_READ	0x18230e38 1 0>,	\
	<DCC_READ	0x18230e3c 1 0>,	\
	<DCC_READ	0x18230e40 1 0>,	\
	<DCC_READ	0x18230e4c 1 0>,	\
	<DCC_READ	0x18230e50 1 0>,	\
	<DCC_READ	0x18230e54 1 0>,	\
	<DCC_READ	0x18230e60 1 0>,	\
	<DCC_READ	0x18230e64 1 0>,	\
	<DCC_READ	0x18230e68 1 0>,	\
	<DCC_READ	0x18230fb0 1 0>,	\
	<DCC_READ	0x18230fb4 1 0>,	\
	<DCC_READ	0x18230fb8 1 0>,	\
	<DCC_READ	0x18230fbc 1 0>,	\
	<DCC_READ	0x18230fd4 1 0>,	\
	<DCC_READ	0x18230fd8 1 0>,	\
	<DCC_READ	0x18230fdc 1 0>,	\
	<DCC_READ	0x18230fe8 1 0>,	\
	<DCC_READ	0x18230fec 1 0>,	\
	<DCC_READ	0x18230ff0 1 0>,	\
	<DCC_READ	0x18230ffc 1 0>,	\
	<DCC_READ	0x18231000 1 0>,	\
	<DCC_READ	0x18231004 1 0>,	\
	<DCC_READ	0x18231010 1 0>,	\
	<DCC_READ	0x18231014 1 0>,	\
	<DCC_READ	0x18231018 1 0>,	\
	<DCC_READ	0x18231024 1 0>,	\
	<DCC_READ	0x18231028 1 0>,	\
	<DCC_READ	0x1823102c 1 0>,	\
	<DCC_READ	0x18231038 1 0>,	\
	<DCC_READ	0x1823103c 1 0>,	\
	<DCC_READ	0x18231040 1 0>,	\
	<DCC_READ	0x1823104c 1 0>,	\
	<DCC_READ	0x18231050 1 0>,	\
	<DCC_READ	0x18231054 1 0>,	\
	<DCC_READ	0x18231060 1 0>,	\
	<DCC_READ	0x18231064 1 0>,	\
	<DCC_READ	0x18231068 1 0>,	\
	<DCC_READ	0x18231074 1 0>,	\
	<DCC_READ	0x18231078 1 0>,	\
	<DCC_READ	0x1823107c 1 0>,	\
	<DCC_READ	0x18231088 1 0>,	\
	<DCC_READ	0x1823108c 1 0>,	\
	<DCC_READ	0x18231090 1 0>,	\
	<DCC_READ	0x1823109c 1 0>,	\
	<DCC_READ	0x182310a0 1 0>,	\
	<DCC_READ	0x182310a4 1 0>,	\
	<DCC_READ	0x182310b0 1 0>,	\
	<DCC_READ	0x182310b4 1 0>,	\
	<DCC_READ	0x182310b8 1 0>,	\
	<DCC_READ	0x182310c4 1 0>,	\
	<DCC_READ	0x182310c8 1 0>,	\
	<DCC_READ	0x182310cc 1 0>,	\
	<DCC_READ	0x182310d8 1 0>,	\
	<DCC_READ	0x182310dc 1 0>,	\
	<DCC_READ	0x182310e0 1 0>,	\
	<DCC_READ	0x182310ec 1 0>,	\
	<DCC_READ	0x182310f0 1 0>,	\
	<DCC_READ	0x182310f4 1 0>,	\
	<DCC_READ	0x18231100 1 0>,	\
	<DCC_READ	0x18231104 1 0>,	\
	<DCC_READ	0x18231108 1 0>,	\
	<DCC_READ	0x18231250 1 0>,	\
	<DCC_READ	0x18231254 1 0>,	\
	<DCC_READ	0x18231258 1 0>,	\
	<DCC_READ	0x1823125c 1 0>,	\
	<DCC_READ	0x18231274 1 0>,	\
	<DCC_READ	0x18231278 1 0>,	\
	<DCC_READ	0x1823127c 1 0>,	\
	<DCC_READ	0x18231288 1 0>,	\
	<DCC_READ	0x1823128c 1 0>,	\
	<DCC_READ	0x18231290 1 0>,	\
	<DCC_READ	0x1823129c 1 0>,	\
	<DCC_READ	0x182312a0 1 0>,	\
	<DCC_READ	0x182312a4 1 0>,	\
	<DCC_READ	0x182312b0 1 0>,	\
	<DCC_READ	0x182312b4 1 0>,	\
	<DCC_READ	0x182312b8 1 0>,	\
	<DCC_READ	0x182312c4 1 0>,	\
	<DCC_READ	0x182312c8 1 0>,	\
	<DCC_READ	0x182312cc 1 0>,	\
	<DCC_READ	0x182312d8 1 0>,	\
	<DCC_READ	0x182312dc 1 0>,	\
	<DCC_READ	0x182312e0 1 0>,	\
	<DCC_READ	0x182312ec 1 0>,	\
	<DCC_READ	0x182312f0 1 0>,	\
	<DCC_READ	0x182312f4 1 0>,	\
	<DCC_READ	0x18231300 1 0>,	\
	<DCC_READ	0x18231304 1 0>,	\
	<DCC_READ	0x18231308 1 0>,	\
	<DCC_READ	0x18231314 1 0>,	\
	<DCC_READ	0x18231318 1 0>,	\
	<DCC_READ	0x1823131c 1 0>,	\
	<DCC_READ	0x18231328 1 0>,	\
	<DCC_READ	0x1823132c 1 0>,	\
	<DCC_READ	0x18231330 1 0>,	\
	<DCC_READ	0x1823133c 1 0>,	\
	<DCC_READ	0x18231340 1 0>,	\
	<DCC_READ	0x18231344 1 0>,	\
	<DCC_READ	0x18231350 1 0>,	\
	<DCC_READ	0x18231354 1 0>,	\
	<DCC_READ	0x18231358 1 0>,	\
	<DCC_READ	0x18231364 1 0>,	\
	<DCC_READ	0x18231368 1 0>,	\
	<DCC_READ	0x1823136c 1 0>,	\
	<DCC_READ	0x18231378 1 0>,	\
	<DCC_READ	0x1823137c 1 0>,	\
	<DCC_READ	0x18231380 1 0>,	\
	<DCC_READ	0x1823138c 1 0>,	\
	<DCC_READ	0x18231390 1 0>,	\
	<DCC_READ	0x18231394 1 0>,	\
	<DCC_READ	0x182313a0 1 0>,	\
	<DCC_READ	0x182313a4 1 0>,	\
	<DCC_READ	0x182313a8 1 0>

#define lito_dcc_async_package				\
	<DCC_WRITE 0x06004FB0 0xc5acce55 0>,	\
	<DCC_WRITE 0x0600408c 0xff 0>,			\
	<DCC_WRITE 0x06004FB0 0x0 0>

#define config_lito_dcc_gcc_other	\
	<DCC_READ 0x100034 3  0>,		\
	<DCC_READ 0x100044 4  0>,		\
	<DCC_READ 0x100114 1  0>,		\
	<DCC_READ 0x100f88 29 0>,		\
	<DCC_READ 0x101034 2  0>,		\
	<DCC_READ 0x101044 4  0>,		\
	<DCC_READ 0x101114 1  0>,		\
	<DCC_READ 0x101fe8 5  0>,		\
	<DCC_READ 0x102034 2  0>,		\
	<DCC_READ 0x102044 4  0>,		\
	<DCC_READ 0x103034 2  0>,		\
	<DCC_READ 0x103044 4  0>,		\
	<DCC_READ 0x104000 4  0>,		\
	<DCC_READ 0x104024 16 0>,		\
	<DCC_READ 0x104134 8  0>,		\
	<DCC_READ 0x104168 16 0>,		\
	<DCC_READ 0x104278 8  0>,		\
	<DCC_READ 0x1042ac 16 0>,		\
	<DCC_READ 0x1043bc 5  0>,		\
	<DCC_READ 0x1043e4 16 0>,		\
	<DCC_READ 0x1044f4 3  0>,		\
	<DCC_READ 0x105000 22 0>,		\
	<DCC_READ 0x10506c 16 0>,		\
	<DCC_READ 0x10517c 2  0>,		\
	<DCC_READ 0x105198 16 0>,		\
	<DCC_READ 0x1052a8 9  0>,		\
	<DCC_READ 0x1052e0 16 0>,		\
	<DCC_READ 0x1053f0 5  0>,		\
	<DCC_READ 0x107000 2  0>,		\
	<DCC_READ 0x108000 3  0>,		\
	<DCC_READ 0x109000 1  0>,		\
	<DCC_READ 0x109028 6  0>,		\
	<DCC_READ 0x109054 16 0>,		\
	<DCC_READ 0x109164 4  0>,		\
	<DCC_READ 0x109188 16 0>,		\
	<DCC_READ 0x109298 4  0>,		\
	<DCC_READ 0x109474 1  0>,		\
	<DCC_READ 0x10a000 3  0>,		\
	<DCC_READ 0x10b000 2  0>,		\
	<DCC_READ 0x10b00c 19 0>,		\
	<DCC_READ 0x10b068 9  0>,		\
	<DCC_READ 0x10c000 20 0>,		\
	<DCC_READ 0x10c064 16 0>,		\
	<DCC_READ 0x10c174 2  0>,		\
	<DCC_READ 0x10c190 16 0>,		\
	<DCC_READ 0x10c2a0 2  0>,		\
	<DCC_READ 0x10c2bc 16 0>,		\
	<DCC_READ 0x10c3cc 2  0>,		\
	<DCC_READ 0x10c3e8 16 0>,		\
	<DCC_READ 0x10c4f8 2  0>,		\
	<DCC_READ 0x10c514 16 0>,		\
	<DCC_READ 0x10c624 2  0>,		\
	<DCC_READ 0x10c63c 2  0>,		\
	<DCC_READ 0x10c658 16 0>,		\
	<DCC_READ 0x10e000 1  0>,		\
	<DCC_READ 0x10f000 13 0>,		\
	<DCC_READ 0x10f038 2  0>,		\
	<DCC_READ 0x10f050 7  0>,		\
	<DCC_READ 0x10f07c 2  0>,		\
	<DCC_READ 0x111000 7  0>,		\
	<DCC_READ 0x111100 2  0>,		\
	<DCC_READ 0x112000 2  0>,		\
	<DCC_READ 0x113034 2  0>,		\
	<DCC_READ 0x113044 4  0>,		\
	<DCC_READ 0x114000 8  0>,		\
	<DCC_READ 0x115000 2  0>,		\
	<DCC_READ 0x116000 8  0>,		\
	<DCC_READ 0x117000 9  0>,		\
	<DCC_READ 0x11702c 8  0>,		\
	<DCC_READ 0x11706c 8  0>,		\
	<DCC_READ 0x1170ac 8  0>,		\
	<DCC_READ 0x1170ec 8  0>,		\
	<DCC_READ 0x11713c 6  0>,		\
	<DCC_READ 0x11715c 8  0>,		\
	<DCC_READ 0x11719c 8  0>,		\
	<DCC_READ 0x1171dc 8  0>,		\
	<DCC_READ 0x11721c 8  0>,		\
	<DCC_READ 0x11726c 6  0>,		\
	<DCC_READ 0x11728c 8  0>,		\
	<DCC_READ 0x1172cc 8  0>,		\
	<DCC_READ 0x11730c 8  0>,		\
	<DCC_READ 0x11734c 8  0>,		\
	<DCC_READ 0x11739c 6  0>,		\
	<DCC_READ 0x1173bc 8  0>,		\
	<DCC_READ 0x1173fc 8  0>,		\
	<DCC_READ 0x11743c 8  0>,		\
	<DCC_READ 0x11747c 8  0>,		\
	<DCC_READ 0x1174cc 6  0>,		\
	<DCC_READ 0x1174ec 8  0>,		\
	<DCC_READ 0x11752c 8  0>,		\
	<DCC_READ 0x11756c 8  0>,		\
	<DCC_READ 0x1175ac 8  0>,		\
	<DCC_READ 0x1175fc 6  0>,		\
	<DCC_READ 0x11761c 8  0>,		\
	<DCC_READ 0x11765c 8  0>,		\
	<DCC_READ 0x11769c 8  0>,		\
	<DCC_READ 0x1176dc 8  0>,		\
	<DCC_READ 0x118000 9  0>,		\
	<DCC_READ 0x11802c 8  0>,		\
	<DCC_READ 0x11806c 8  0>,		\
	<DCC_READ 0x1180ac 8  0>,		\
	<DCC_READ 0x1180ec 8  0>,		\
	<DCC_READ 0x11813c 6  0>,		\
	<DCC_READ 0x11815c 8  0>,		\
	<DCC_READ 0x11819c 8  0>,		\
	<DCC_READ 0x1181dc 8  0>,		\
	<DCC_READ 0x11821c 8  0>,		\
	<DCC_READ 0x11826c 6  0>,		\
	<DCC_READ 0x11828c 8  0>,		\
	<DCC_READ 0x1182cc 8  0>,		\
	<DCC_READ 0x11830c 8  0>,		\
	<DCC_READ 0x11834c 8  0>,		\
	<DCC_READ 0x11839c 6  0>,		\
	<DCC_READ 0x1183bc 8  0>,		\
	<DCC_READ 0x1183fc 8  0>,		\
	<DCC_READ 0x11843c 8  0>,		\
	<DCC_READ 0x11847c 8  0>,		\
	<DCC_READ 0x1184cc 6  0>,		\
	<DCC_READ 0x1184ec 8  0>,		\
	<DCC_READ 0x11852c 8  0>,		\
	<DCC_READ 0x11856c 8  0>,		\
	<DCC_READ 0x1185ac 8  0>,		\
	<DCC_READ 0x1185fc 6  0>,		\
	<DCC_READ 0x11861c 8  0>,		\
	<DCC_READ 0x11865c 8  0>,		\
	<DCC_READ 0x11869c 8  0>,		\
	<DCC_READ 0x1186dc 8  0>,		\
	<DCC_READ 0x119000 4  0>,		\
	<DCC_READ 0x119014 7  0>,		\
	<DCC_READ 0x11903c 4  0>,		\
	<DCC_READ 0x119050 7  0>,		\
	<DCC_READ 0x119070 1  0>,		\
	<DCC_READ 0x11a034 2  0>,		\
	<DCC_READ 0x11a044 4  0>,		\
	<DCC_READ 0x11aff0 3  0>,		\
	<DCC_READ 0x11b034 2  0>,		\
	<DCC_READ 0x11b044 4  0>,		\
	<DCC_READ 0x11c034 2  0>,		\
	<DCC_READ 0x11c044 4  0>,		\
	<DCC_READ 0x11d034 2  0>,		\
	<DCC_READ 0x11d044 4  0>,		\
	<DCC_READ 0x120000 1  0>,		\
	<DCC_READ 0x121000 1  0>,		\
	<DCC_READ 0x122000 2  0>,		\
	<DCC_READ 0x123000 5  0>,		\
	<DCC_READ 0x123028 16 0>,		\
	<DCC_READ 0x123138 5  0>,		\
	<DCC_READ 0x123160 16 0>,		\
	<DCC_READ 0x124000 2  0>,		\
	<DCC_READ 0x125000 5  0>,		\
	<DCC_READ 0x126000 5  0>,		\
	<DCC_READ 0x126024 5  0>,		\
	<DCC_READ 0x12603c 1  0>,		\
	<DCC_READ 0x132000 1  0>,		\
	<DCC_READ 0x133000 6  0>,		\
	<DCC_READ 0x133028 1  0>,		\
	<DCC_READ 0x134000 2  0>,		\
	<DCC_READ 0x135004 2  0>,		\
	<DCC_READ 0x135014 6  0>,		\
	<DCC_READ 0x135124 1  0>,		\
	<DCC_READ 0x136024 2  0>,		\
	<DCC_READ 0x137000 2  0>,		\
	<DCC_READ 0x138000 2  0>,		\
	<DCC_READ 0x139000 1  0>,		\
	<DCC_READ 0x13a000 6  0>,		\
	<DCC_READ 0x13c000 4  0>,		\
	<DCC_READ 0x13d000 8  0>,		\
	<DCC_READ 0x13d030 2  0>,		\
	<DCC_READ 0x13e030 1  0>,		\
	<DCC_READ 0x140000 10 0>,		\
	<DCC_READ 0x141000 6  0>,		\
	<DCC_READ 0x14102c 16 0>,		\
	<DCC_READ 0x142000 1  0>,		\
	<DCC_READ 0x143000 8  0>,		\
	<DCC_READ 0x143030 2  0>,		\
	<DCC_READ 0x144000 7  0>,		\
	<DCC_READ 0x144020 3  0>,		\
	<DCC_READ 0x144040 16 0>,		\
	<DCC_READ 0x144150 2  0>,		\
	<DCC_READ 0x14416c 16 0>,		\
	<DCC_READ 0x14427c 2  0>,		\
	<DCC_READ 0x144288 3  0>,		\
	<DCC_READ 0x1442a8 16 0>,		\
	<DCC_READ 0x1443b8 3  0>,		\
	<DCC_READ 0x1443d8 16 0>,		\
	<DCC_READ 0x1444e8 2  0>,		\
	<DCC_READ 0x144530 1  0>,		\
	<DCC_READ 0x14500c 1  0>,		\
	<DCC_READ 0x145014 1  0>,		\
	<DCC_READ 0x14501c 7  0>,		\
	<DCC_READ 0x14504c 16 0>,		\
	<DCC_READ 0x14515c 3  0>,		\
	<DCC_READ 0x145388 4  0>,		\
	<DCC_READ 0x145490 1  0>,		\
	<DCC_READ 0x146000 5  0>,		\
	<DCC_READ 0x147000 6  0>,		\
	<DCC_READ 0x148000 6  0>,		\
	<DCC_READ 0x148024 4  0>,		\
	<DCC_READ 0x148044 2  0>,		\
	<DCC_READ 0x14805c 4  0>,		\
	<DCC_READ 0x149000 4  0>,		\
	<DCC_READ 0x14a004 1  0>,		\
	<DCC_READ 0x14c000 1  0>,		\
	<DCC_READ 0x14d000 9  0>,		\
	<DCC_READ 0x14d038 16 0>,		\
	<DCC_READ 0x14d110 1  0>,		\
	<DCC_READ 0x14d148 1  0>,		\
	<DCC_READ 0x14e000 5  0>,		\
	<DCC_READ 0x14f000 5  0>,		\
	<DCC_READ 0x150000 6  0>,		\
	<DCC_READ 0x151000 6  0>,		\
	<DCC_READ 0x151124 1  0>,		\
	<DCC_READ 0x152000 6  0>,		\
	<DCC_READ 0x152124 1  0>,		\
	<DCC_READ 0x153000 11 0>,		\
	<DCC_READ 0x153124 1  0>,		\
	<DCC_READ 0x154000 6  0>,		\
	<DCC_READ 0x154124 1  0>,		\
	<DCC_READ 0x155000 6  0>,		\
	<DCC_READ 0x155124 1  0>,		\
	<DCC_READ 0x156000 6  0>,		\
	<DCC_READ 0x156124 1  0>,		\
	<DCC_READ 0x157000 6  0>,		\
	<DCC_READ 0x15a000 6  0>,		\
	<DCC_READ 0x15a124 1  0>,		\
	<DCC_READ 0x15b000 6  0>,		\
	<DCC_READ 0x15b024 1  0>,		\
	<DCC_READ 0x162000 4  0>,		\
	<DCC_READ 0x162018 3  0>,		\
	<DCC_READ 0x162030 4  0>,		\
	<DCC_READ 0x164000 6  0>,		\
	<DCC_READ 0x165000 6  0>,		\
	<DCC_READ 0x166000 6  0>,		\
	<DCC_READ 0x167020 1  0>,		\
	<DCC_READ 0x168000 1  0>,		\
	<DCC_READ 0x169000 6  0>,		\
	<DCC_READ 0x169124 1  0>,		\
	<DCC_READ 0x16a000 2  0>,		\
	<DCC_READ 0x16d000 1  0>,		\
	<DCC_READ 0x16e000 1  0>,		\
	<DCC_READ 0x170000 4  0>,		\
	<DCC_READ 0x171000 4  0>,		\
	<DCC_READ 0x171014 4  0>,		\
	<DCC_READ 0x171028 1  0>,		\
	<DCC_READ 0x171038 16 0>,		\
	<DCC_READ 0x171148 4  0>,		\
	<DCC_READ 0x17300c 3  0>,		\
	<DCC_READ 0x174034 2  0>,		\
	<DCC_READ 0x174044 4  0>,		\
	<DCC_READ 0x174fec 4  0>,		\
	<DCC_READ 0x176034 2  0>,		\
	<DCC_READ 0x176044 4  0>,		\
	<DCC_READ 0x176fec 4  0>,		\
	<DCC_READ 0x177000 14 0>,		\
	<DCC_READ 0x17703c 14 0>,		\
	<DCC_READ 0x177084 2  0>,		\
	<DCC_READ 0x17709c 3  0>,		\
	<DCC_READ 0x1770b8 6  0>,		\
	<DCC_READ 0x178030 1  0>,		\
	<DCC_READ 0x17a000 8  0>,		\
	<DCC_READ 0x17a030 2  0>,		\
	<DCC_READ 0x17a048 4  0>,		\
	<DCC_READ 0x17b000 4  0>,		\
	<DCC_READ 0x17b014 7  0>,		\
	<DCC_READ 0x17b03c 4  0>,		\
	<DCC_READ 0x17b050 7  0>,		\
	<DCC_READ 0x17b070 1  0>,		\
	<DCC_READ 0x17c000 4  0>,		\
	<DCC_READ 0x17c014 7  0>,		\
	<DCC_READ 0x17c03c 4  0>,		\
	<DCC_READ 0x17c050 7  0>,		\
	<DCC_READ 0x17c070 1  0>,		\
	<DCC_READ 0x17d000 4  0>,		\
	<DCC_READ 0x17d014 7  0>,		\
	<DCC_READ 0x17d03c 4  0>,		\
	<DCC_READ 0x17d050 7  0>,		\
	<DCC_READ 0x17d070 1  0>,		\
	<DCC_READ 0x17e000 4  0>,		\
	<DCC_READ 0x17e014 7  0>,		\
	<DCC_READ 0x17e03c 4  0>,		\
	<DCC_READ 0x17e050 7  0>,		\
	<DCC_READ 0x17e070 1  0>,		\
	<DCC_READ 0x17f000 1  0>,		\
	<DCC_READ 0x180000 7  0>,		\
	<DCC_READ 0x181000 1  0>,		\
	<DCC_READ 0x182000 14 0>,		\
	<DCC_READ 0x18204c 16 0>,		\
	<DCC_READ 0x18215c 6  0>,		\
	<DCC_READ 0x182188 16 0>,		\
	<DCC_READ 0x182298 4  0>,		\
	<DCC_READ 0x182890 1  0>,		\
	<DCC_READ 0x183000 1  0>,		\
	<DCC_READ 0x183010 2  0>,		\
	<DCC_READ 0x18302c 16 0>,		\
	<DCC_READ 0x18313c 1  0>,		\
	<DCC_READ 0x184000 2  0>,		\
	<DCC_READ 0x187000 4  0>,		\
	<DCC_READ 0x187014 7  0>,		\
	<DCC_READ 0x18703c 4  0>,		\
	<DCC_READ 0x187050 7  0>,		\
	<DCC_READ 0x187070 1  0>,		\
	<DCC_READ 0x188000 2  0>,		\
	<DCC_READ 0x189000 1  0>,		\
	<DCC_READ 0x189020 1  0>,		\
	<DCC_READ 0x189028 4  0>,		\
	<DCC_READ 0x18904c 16 0>,		\
	<DCC_READ 0x18915c 2  0>,		\
	<DCC_READ 0x18a000 1  0>,		\
	<DCC_READ 0x18a008 5  0>,		\
	<DCC_READ 0x18a030 16 0>,		\
	<DCC_READ 0x18a140 1  0>,		\
	<DCC_READ 0x18a148 4  0>,		\
	<DCC_READ 0x18a16c 16 0>,		\
	<DCC_READ 0x18a27c 5  0>,		\
	<DCC_READ 0x18a308 2  0>,		\
	<DCC_READ 0x18c000 1  0>,		\
	<DCC_READ 0x18c010 5  0>,		\
	<DCC_READ 0x18d004 2  0>,		\
	<DCC_READ 0x18f000 1  0>,		\
	<DCC_READ 0x19000  1	0>,		\
	<DCC_READ 0x191004 16 0>,		\
	<DCC_READ 0x192004 16 0>,		\
	<DCC_READ 0x193004 16 0>,		\
	<DCC_READ 0x194004 16 0>,		\
	<DCC_READ 0x195004 16 0>,		\
	<DCC_READ 0x196004 16 0>,		\
	<DCC_READ 0x197004 16 0>,		\
	<DCC_READ 0x198004 16 0>,		\
	<DCC_READ 0x199004 16 0>,		\
	<DCC_READ 0x199080 1	0>,		\
	<DCC_READ 0x19a004 16 0>,		\
	<DCC_READ 0x19b004 16 0>,		\
	<DCC_READ 0x19c004 16 0>

#define	config_lito_dcc_gic		\
	/* GIC for lito start */		\
	<DCC_READ	0x17A2E000	1 0>,	\
	<DCC_READ	0x17A00200 	29 0>,	\
	<DCC_READ	0x17A00100 	29 0>,	\
	<DCC_READ	0x17A2FFC8 	1 0>,	\
	<DCC_READ	0x17A20008 	1 0>,	\
	<DCC_READ	0x17A20010 	1 0>,	\
	<DCC_READ	0x17A20020 	1 0>,	\
	<DCC_READ	0x17A20048 	1 0>,	\
	<DCC_READ	0x17A20050 	1 0>,	\
	<DCC_READ	0x17A20060 	1 0>,	\
	<DCC_READ	0x17A20088 	1 0>,	\
	<DCC_READ	0x17A20090 	1 0>,	\
	<DCC_READ	0x17A200A0 	1 0>,	\
	<DCC_READ	0x17A200C8 	1 0>,	\
	<DCC_READ	0x17A200D0 	1 0>,	\
	<DCC_READ	0x17A200E0 	1 0>,	\
	<DCC_READ	0x17A20108 	1 0>,	\
	<DCC_READ	0x17A20110 	1 0>,	\
	<DCC_READ	0x17A20120 	1 0>,	\
	<DCC_READ	0x17A20148 	1 0>,	\
	<DCC_READ	0x17A20150 	1 0>,	\
	<DCC_READ	0x17A20160 	1 0>,	\
	<DCC_READ	0x17A20188 	1 0>,	\
	<DCC_READ	0x17A20190 	1 0>,	\
	<DCC_READ	0x17A201A0 	1 0>,	\
	<DCC_READ	0x17A201C8 	1 0>,	\
	<DCC_READ	0x17A201D0 	1 0>,	\
	<DCC_READ	0x17A201E0 	1 0>,	\
	<DCC_READ	0x17A20208 	1 0>,	\
	<DCC_READ	0x17A20210 	1 0>,	\
	<DCC_READ	0x17A20220 	1 0>,	\
	<DCC_READ	0x17A20248 	1 0>,	\
	<DCC_READ	0x17A20250 	1 0>,	\
	<DCC_READ	0x17A20260 	1 0>,	\
	<DCC_READ	0x17A20288 	1 0>,	\
	<DCC_READ	0x17A20290 	1 0>,	\
	<DCC_READ	0x17A202A0 	1 0>,	\
	<DCC_READ	0x17A202C8 	1 0>,	\
	<DCC_READ	0x17A202D0 	1 0>,	\
	<DCC_READ	0x17A202E0 	1 0>,	\
	<DCC_READ	0x17A20308 	1 0>,	\
	<DCC_READ	0x17A20310 	1 0>,	\
	<DCC_READ	0x17A20320 	1 0>,	\
	<DCC_READ	0x17A20348 	1 0>,	\
	<DCC_READ	0x17A20350 	1 0>,	\
	<DCC_READ	0x17A20360 	1 0>

#define config_lito_dcc_rpdm_dpcc				\
	<DCC_READ	0x090C80D4	1 0>,	\
	<DCC_READ	0x090C80D0	1 0>,	\
	<DCC_READ	0x090C80A0	1 0>,	\
	<DCC_READ	0x090C8068	1 0>,	\
	<DCC_READ	0x00634094	1 0>

&dcc {
	dcc_curr_link@6 {
		qcom,data-sink = "sram";
		qcom,curr-link-list = <6>;
		qcom,link-list =
			config_lito_dcc_lpm,
			config_lito_dcc_apps_rsc_pdc,
			config_lito_dcc_core,
			config_lito_dcc_osm,
			config_lito_dcc_gemnoc,
			config_lito_dcc_noc,
			config_lito_dcc_gcc,
			config_lito_dcc_pimem,
			config_lito_dcc_misc,
			config_lito_dcc_ddr,
			config_lito_dcc_ddr,
			config_lito_dcc_gic,
			config_lito_dcc_rpdm_dpcc;
	};

	dcc_curr_link@4 {
		qcom,data-sink = "sram";
		qcom,curr-link-list = <4>;
		qcom,link-list =
//			config_lito_dcc_gemnoc,
//			config_lito_dcc_noc,
//			config_lito_dcc_cam;
			config_lito_dcc_rpdm_dpcc;
	};


	dcc_curr_link@3 {
		qcom,data-sink = "atb";
		qcom,curr-link-list = <3>;
		qcom,link-list =
//			lito_dcc_async_package,
//			config_lito_dcc_rsc_tcs,
//			config_lito_dcc_lpass_rsc,
//			config_lito_dcc_mss_rsc,
//			config_lito_dcc_l3_rsc,
//			config_lito_dcc_gcc_other;
			config_lito_dcc_rpdm_dpcc;
	};

	link_list1 {
		qcom,curr-link-list = <0xFF>;
	};

	link_list2 {
		qcom,curr-link-list = <0xFF>;
	};

	link_list3 {
		qcom,curr-link-list = <0xFF>;
	};
};
